AUTOSAR XML (schema 4-2-2)
package /STELLANTIS/EPT/ASWCs
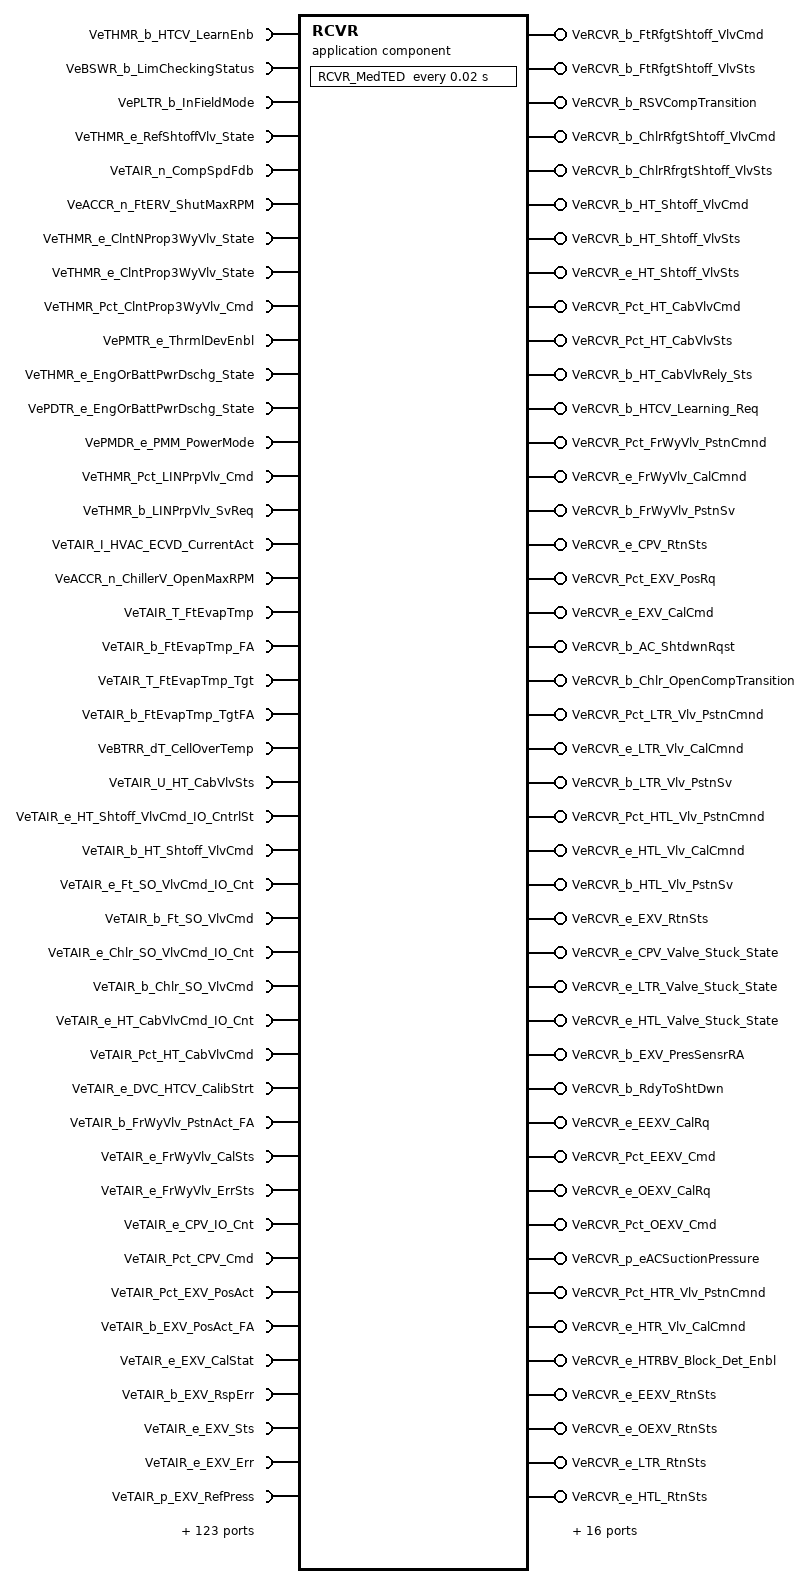
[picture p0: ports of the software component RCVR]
  application sw component type RCVR
    156 x require port:
      VeTHMR_b_HTCV_LearnEnb: variation-point={short-label=vpVeTHMR_b_HTCV_LearnEnb, sw-syscond=1}, nonqueued-receiver-com-spec{data-element=Value, init-value=0}, required-interface=VeTHMR_b_HTCV_LearnEnb
      VeBSWR_b_LimCheckingStatus: variation-point={short-label=vpVeBSWR_b_LimCheckingStatus, sw-syscond=1}, nonqueued-receiver-com-spec{data-element=Value, init-value=0}, required-interface=VeBSWR_b_LimCheckingStatus
      VePLTR_b_InFieldMode: variation-point={short-label=vpVePLTR_b_InFieldMode, sw-syscond=1}, nonqueued-receiver-com-spec{data-element=Value, init-value=0}, required-interface=VePLTR_b_InFieldMode
      VeTHMR_e_RefShtoffVlv_State: variation-point={short-label=vpVeTHMR_e_RefShtoffVlv_State, sw-syscond=1}, nonqueued-receiver-com-spec{data-element=Value, init-value=CeTHMR_e_AllOpen}, required-interface=VeTHMR_e_RefShtoffVlv_State
      VeTAIR_n_CompSpdFdb: variation-point={short-label=vpVeTAIR_n_CompSpdFdb, sw-syscond=1}, nonqueued-receiver-com-spec{data-element=Value, init-value=0}, required-interface=VeTAIR_n_CompSpdFdb
      VeACCR_n_FtERV_ShutMaxRPM: variation-point={short-label=vpVeACCR_n_FtERV_ShutMaxRPM, sw-syscond=1}, nonqueued-receiver-com-spec{data-element=Value, init-value=0}, required-interface=VeACCR_n_FtERV_ShutMaxRPM
      VeTHMR_e_ClntNProp3WyVlv_State: variation-point={short-label=vpVeTHMR_e_ClntNProp3WyVlv_State, sw-syscond=1}, nonqueued-receiver-com-spec{data-element=Value, init-value=CeTHMR_e_NoVlvPwrd}, required-interface=VeTHMR_e_ClntNProp3WyVlv_State
      VeTHMR_e_ClntProp3WyVlv_State: variation-point={short-label=vpVeTHMR_e_ClntProp3WyVlv_State, sw-syscond=1}, nonqueued-receiver-com-spec{data-element=Value, init-value=CeTHMR_e_NoVlvPwrd}, required-interface=VeTHMR_e_ClntProp3WyVlv_State
      VeTHMR_Pct_ClntProp3WyVlv_Cmd: variation-point={short-label=vpVeTHMR_Pct_ClntProp3WyVlv_Cmd, sw-syscond=1}, nonqueued-receiver-com-spec{data-element=Value, init-value=0}, required-interface=VeTHMR_Pct_ClntProp3WyVlv_Cmd
      VePMTR_e_ThrmlDevEnbl: variation-point={short-label=vpVePMTR_e_ThrmlDevEnbl, sw-syscond=1}, nonqueued-receiver-com-spec{data-element=Value, init-value=CePMTR_e_DISBL_All_Thrml}, required-interface=VePMTR_e_ThrmlDevEnbl
      VeTHMR_e_EngOrBattPwrDschg_State: variation-point={short-label=vpVeTHMR_e_EngOrBattPwrDschg_State, sw-syscond=1}, nonqueued-receiver-com-spec{data-element=Value, init-value=CePDTR_e_No_Dischrg}, required-interface=VeTHMR_e_EngOrBattPwrDschg_State
      VePDTR_e_EngOrBattPwrDschg_State: variation-point={short-label=vpVePDTR_e_EngOrBattPwrDschg_State, sw-syscond=1}, nonqueued-receiver-com-spec{data-element=Value, init-value=CePDTR_e_No_Dischrg}, required-interface=VePDTR_e_EngOrBattPwrDschg_State
      VePMDR_e_PMM_PowerMode: variation-point={short-label=vpVePMDR_e_PMM_PowerMode, sw-syscond=1}, nonqueued-receiver-com-spec{data-element=Value, init-value=CePMDR_e_PowerMode_Off}, required-interface=VePMDR_e_PMM_PowerMode
      VeTHMR_Pct_LINPrpVlv_Cmd: variation-point={short-label=vpVeTHMR_Pct_LINPrpVlv_Cmd, sw-syscond=1}, nonqueued-receiver-com-spec{data-element=Value, init-value=0}, required-interface=VeTHMR_Pct_LINPrpVlv_Cmd
      VeTHMR_b_LINPrpVlv_SvReq: variation-point={short-label=vpVeTHMR_b_LINPrpVlv_SvReq, sw-syscond=1}, nonqueued-receiver-com-spec{data-element=Value, init-value=0}, required-interface=VeTHMR_b_LINPrpVlv_SvReq
      VeTAIR_I_HVAC_ECVD_CurrentAct: variation-point={short-label=vpVeTAIR_I_HVAC_ECVD_CurrentAct, sw-syscond=1}, nonqueued-receiver-com-spec{data-element=Value, init-value=0}, required-interface=VeTAIR_I_HVAC_ECVD_CurrentAct
      VeACCR_n_ChillerV_OpenMaxRPM: variation-point={short-label=vpVeACCR_n_ChillerV_OpenMaxRPM, sw-syscond=1}, nonqueued-receiver-com-spec{data-element=Value, init-value=0}, required-interface=VeACCR_n_ChillerV_OpenMaxRPM
      VeTAIR_T_FtEvapTmp: variation-point={short-label=vpVeTAIR_T_FtEvapTmp, sw-syscond=1}, nonqueued-receiver-com-spec{data-element=Value, init-value=0}, required-interface=VeTAIR_T_FtEvapTmp
      VeTAIR_b_FtEvapTmp_FA: variation-point={short-label=vpVeTAIR_b_FtEvapTmp_FA, sw-syscond=1}, nonqueued-receiver-com-spec{data-element=Value, init-value=0}, required-interface=VeTAIR_b_FtEvapTmp_FA
      VeTAIR_T_FtEvapTmp_Tgt: variation-point={short-label=vpVeTAIR_T_FtEvapTmp_Tgt, sw-syscond=1}, nonqueued-receiver-com-spec{data-element=Value, init-value=0}, required-interface=VeTAIR_T_FtEvapTmp_Tgt
      VeTAIR_b_FtEvapTmp_TgtFA: variation-point={short-label=vpVeTAIR_b_FtEvapTmp_TgtFA, sw-syscond=1}, nonqueued-receiver-com-spec{data-element=Value, init-value=0}, required-interface=VeTAIR_b_FtEvapTmp_TgtFA
      VeBTRR_dT_CellOverTemp: variation-point={short-label=vpVeBTRR_dT_CellOverTemp, sw-syscond=1}, nonqueued-receiver-com-spec{data-element=Value, init-value=0}, required-interface=VeBTRR_dT_CellOverTemp
      VeTAIR_U_HT_CabVlvSts: variation-point={short-label=vpVeTAIR_U_HT_CabVlvSts, sw-syscond=1}, nonqueued-receiver-com-spec{data-element=Value, init-value=0}, required-interface=VeTAIR_U_HT_CabVlvSts
      VeTAIR_e_HT_Shtoff_VlvCmd_IO_CntrlSt: variation-point={short-label=vpVeTAIR_e_HT_Shtoff_VlvCmd_IO_CntrlSt, sw-syscond=1}, nonqueued-receiver-com-spec{data-element=Value, init-value=CeTAIR_e_Return_Control_to_ECU}, required-interface=VeTAIR_e_HT_Shtoff_VlvCmd_IO_CntrlSt
      VeTAIR_b_HT_Shtoff_VlvCmd: variation-point={short-label=vpVeTAIR_b_HT_Shtoff_VlvCmd, sw-syscond=1}, nonqueued-receiver-com-spec{data-element=Value, init-value=0}, required-interface=VeTAIR_b_HT_Shtoff_VlvCmd
      VeTAIR_e_Ft_SO_VlvCmd_IO_Cnt: variation-point={short-label=vpVeTAIR_e_Ft_SO_VlvCmd_IO_Cnt, sw-syscond=1}, nonqueued-receiver-com-spec{data-element=Value, init-value=CeTAIR_e_Return_Control_to_ECU}, required-interface=VeTAIR_e_Ft_SO_VlvCmd_IO_Cnt
      VeTAIR_b_Ft_SO_VlvCmd: variation-point={short-label=vpVeTAIR_b_Ft_SO_VlvCmd, sw-syscond=1}, nonqueued-receiver-com-spec{data-element=Value, init-value=0}, required-interface=VeTAIR_b_Ft_SO_VlvCmd
      VeTAIR_e_Chlr_SO_VlvCmd_IO_Cnt: variation-point={short-label=vpVeTAIR_e_Chlr_SO_VlvCmd_IO_Cnt, sw-syscond=1}, nonqueued-receiver-com-spec{data-element=Value, init-value=CeTAIR_e_Return_Control_to_ECU}, required-interface=VeTAIR_e_Chlr_SO_VlvCmd_IO_Cnt
      VeTAIR_b_Chlr_SO_VlvCmd: variation-point={short-label=vpVeTAIR_b_Chlr_SO_VlvCmd, sw-syscond=1}, nonqueued-receiver-com-spec{data-element=Value, init-value=0}, required-interface=VeTAIR_b_Chlr_SO_VlvCmd
      VeTAIR_e_HT_CabVlvCmd_IO_Cnt: variation-point={short-label=vpVeTAIR_e_HT_CabVlvCmd_IO_Cnt, sw-syscond=1}, nonqueued-receiver-com-spec{data-element=Value, init-value=CeTAIR_e_Return_Control_to_ECU}, required-interface=VeTAIR_e_HT_CabVlvCmd_IO_Cnt
      VeTAIR_Pct_HT_CabVlvCmd: variation-point={short-label=vpVeTAIR_Pct_HT_CabVlvCmd, sw-syscond=1}, nonqueued-receiver-com-spec{data-element=Value, init-value=0}, required-interface=VeTAIR_Pct_HT_CabVlvCmd
      VeTAIR_e_DVC_HTCV_CalibStrt: variation-point={short-label=vpVeTAIR_e_DVC_HTCV_CalibStrt, sw-syscond=1}, nonqueued-receiver-com-spec{data-element=Value, init-value=CeTAIR_e_DVC_HTCV_Calibration_Start}, required-interface=VeTAIR_e_DVC_HTCV_CalibStrt
      VeTAIR_b_FrWyVlv_PstnAct_FA: variation-point={short-label=vpVeTAIR_b_FrWyVlv_PstnAct_FA, sw-syscond=1}, nonqueued-receiver-com-spec{data-element=Value, init-value=0}, required-interface=VeTAIR_b_FrWyVlv_PstnAct_FA
      VeTAIR_e_FrWyVlv_CalSts: variation-point={short-label=vpVeTAIR_e_FrWyVlv_CalSts, sw-syscond=1}, nonqueued-receiver-com-spec{data-element=Value, init-value=CeTAIR_e_CPV_Calibration_Complete}, required-interface=VeTAIR_e_FrWyVlv_CalSts
      VeTAIR_e_FrWyVlv_ErrSts: variation-point={short-label=vpVeTAIR_e_FrWyVlv_ErrSts, sw-syscond=1}, nonqueued-receiver-com-spec{data-element=Value, init-value=CeTAIR_e_CPV_Status_OK}, required-interface=VeTAIR_e_FrWyVlv_ErrSts
      VeTAIR_e_CPV_IO_Cnt: variation-point={short-label=vpVeTAIR_e_CPV_IO_Cnt, sw-syscond=1}, nonqueued-receiver-com-spec{data-element=Value, init-value=CeTAIR_e_Return_Control_to_ECU}, required-interface=VeTAIR_e_CPV_IO_Cnt
      VeTAIR_Pct_CPV_Cmd: variation-point={short-label=vpVeTAIR_Pct_CPV_Cmd, sw-syscond=1}, nonqueued-receiver-com-spec{data-element=Value, init-value=0}, required-interface=VeTAIR_Pct_CPV_Cmd
      VeTAIR_Pct_EXV_PosAct: variation-point={short-label=vpVeTAIR_Pct_EXV_PosAct, sw-syscond=1}, nonqueued-receiver-com-spec{data-element=Value, init-value=0}, required-interface=VeTAIR_Pct_EXV_PosAct
      VeTAIR_b_EXV_PosAct_FA: variation-point={short-label=vpVeTAIR_b_EXV_PosAct_FA, sw-syscond=1}, nonqueued-receiver-com-spec{data-element=Value, init-value=0}, required-interface=VeTAIR_b_EXV_PosAct_FA
      VeTAIR_e_EXV_CalStat: variation-point={short-label=vpVeTAIR_e_EXV_CalStat, sw-syscond=1}, nonqueued-receiver-com-spec{data-element=Value, init-value=CeTAIR_e_EXV_Calibration_Complete}, required-interface=VeTAIR_e_EXV_CalStat
      VeTAIR_b_EXV_RspErr: variation-point={short-label=vpVeTAIR_b_EXV_RspErr, sw-syscond=1}, nonqueued-receiver-com-spec{data-element=Value, init-value=0}, required-interface=VeTAIR_b_EXV_RspErr
      VeTAIR_e_EXV_Sts: variation-point={short-label=vpVeTAIR_e_EXV_Sts, sw-syscond=1}, nonqueued-receiver-com-spec{data-element=Value, init-value=CeTAIR_e_EXV_Status_OK}, required-interface=VeTAIR_e_EXV_Sts
      VeTAIR_e_EXV_Err: variation-point={short-label=vpVeTAIR_e_EXV_Err, sw-syscond=1}, nonqueued-receiver-com-spec{data-element=Value, init-value=CeTAIR_e_EXV_ErrorMsg_OK}, required-interface=VeTAIR_e_EXV_Err
      VeTAIR_p_EXV_RefPress: variation-point={short-label=vpVeTAIR_p_EXV_RefPress, sw-syscond=1}, nonqueued-receiver-com-spec{data-element=Value, init-value=0}, required-interface=VeTAIR_p_EXV_RefPress
      VeTAIR_b_EXV_RefPress_FA: variation-point={short-label=vpVeTAIR_b_EXV_RefPress_FA, sw-syscond=1}, nonqueued-receiver-com-spec{data-element=Value, init-value=0}, required-interface=VeTAIR_b_EXV_RefPress_FA
      VeTAIR_T_EXV_RefTemp: variation-point={short-label=vpVeTAIR_T_EXV_RefTemp, sw-syscond=1}, nonqueued-receiver-com-spec{data-element=Value, init-value=0}, required-interface=VeTAIR_T_EXV_RefTemp
      VeTAIR_b_EXV_RefTemp_FA: variation-point={short-label=vpVeTAIR_b_EXV_RefTemp_FA, sw-syscond=1}, nonqueued-receiver-com-spec{data-element=Value, init-value=0}, required-interface=VeTAIR_b_EXV_RefTemp_FA
      VeVLDR_b_HTSoV_StkCls_XYEnbl: variation-point={short-label=vpVeVLDR_b_HTSoV_StkCls_XYEnbl, sw-syscond=1}, nonqueued-receiver-com-spec{data-element=Value, init-value=0}, required-interface=VeVLDR_b_HTSoV_StkCls_XYEnbl
      VeVLDR_b_HTSoV_StkOpn_XYEnbl: variation-point={short-label=vpVeVLDR_b_HTSoV_StkOpn_XYEnbl, sw-syscond=1}, nonqueued-receiver-com-spec{data-element=Value, init-value=0}, required-interface=VeVLDR_b_HTSoV_StkOpn_XYEnbl
      VeVLDR_b_HTSoV_StkCls_FltDtct: variation-point={short-label=vpVeVLDR_b_HTSoV_StkCls_FltDtct, sw-syscond=1}, nonqueued-receiver-com-spec{data-element=Value, init-value=0}, required-interface=VeVLDR_b_HTSoV_StkCls_FltDtct
      VeVLDR_b_HTSoV_StkOpn_FltDtct: variation-point={short-label=vpVeVLDR_b_HTSoV_StkOpn_FltDtct, sw-syscond=1}, nonqueued-receiver-com-spec{data-element=Value, init-value=0}, required-interface=VeVLDR_b_HTSoV_StkOpn_FltDtct
      VeVLDR_b_HTCV_Stck_FltDtct: variation-point={short-label=vpVeVLDR_b_HTCV_Stck_FltDtct, sw-syscond=1}, nonqueued-receiver-com-spec{data-element=Value, init-value=0}, required-interface=VeVLDR_b_HTCV_Stck_FltDtct
      VeVLDR_b_HCTV_Leak_FltDtct: variation-point={short-label=vpVeVLDR_b_HCTV_Leak_FltDtct, sw-syscond=1}, nonqueued-receiver-com-spec{data-element=Value, init-value=0}, required-interface=VeVLDR_b_HCTV_Leak_FltDtct
      VeVLDR_b_EXV_PressElctrFlt_FltDtct: variation-point={short-label=vpVeVLDR_b_EXV_PressElctrFlt_FltDtct, sw-syscond=1}, nonqueued-receiver-com-spec{data-element=Value, init-value=0}, required-interface=VeVLDR_b_EXV_PressElctrFlt_FltDtct
      VeVLDR_b_EXV_TempElctrFlt_FltDtct: variation-point={short-label=vpVeVLDR_b_EXV_TempElctrFlt_FltDtct, sw-syscond=1}, nonqueued-receiver-com-spec{data-element=Value, init-value=0}, required-interface=VeVLDR_b_EXV_TempElctrFlt_FltDtct
      VeTAIR_b_LTR_BypsVlv_ActlPstn_FA: variation-point={short-label=vpVeTAIR_b_LTR_BypsVlv_ActlPstn_FA, sw-syscond=1}, nonqueued-receiver-com-spec{data-element=Value, init-value=0}, required-interface=VeTAIR_b_LTR_BypsVlv_ActlPstn_FA
      VeTAIR_e_LTR_BypsVlv_ErrSts: variation-point={short-label=vpVeTAIR_e_LTR_BypsVlv_ErrSts, sw-syscond=1}, nonqueued-receiver-com-spec{data-element=Value, init-value=CeTAIR_e_CPV_Status_OK}, required-interface=VeTAIR_e_LTR_BypsVlv_ErrSts
      VeTAIR_e_LTR_BypsVlv_CalSts: variation-point={short-label=vpVeTAIR_e_LTR_BypsVlv_CalSts, sw-syscond=1}, nonqueued-receiver-com-spec{data-element=Value, init-value=CeTAIR_e_CPV_Calibration_Complete}, required-interface=VeTAIR_e_LTR_BypsVlv_CalSts
      VeTAIR_b_HTL_BypsVlv_ActlPstn_FA: variation-point={short-label=vpVeTAIR_b_HTL_BypsVlv_ActlPstn_FA, sw-syscond=1}, nonqueued-receiver-com-spec{data-element=Value, init-value=0}, required-interface=VeTAIR_b_HTL_BypsVlv_ActlPstn_FA
      VeTAIR_e_HTL_BypsVlv_ErrSts: variation-point={short-label=vpVeTAIR_e_HTL_BypsVlv_ErrSts, sw-syscond=1}, nonqueued-receiver-com-spec{data-element=Value, init-value=CeTAIR_e_CPV_Status_OK}, required-interface=VeTAIR_e_HTL_BypsVlv_ErrSts
      VeTAIR_e_HTL_BypsVlv_CalSts: variation-point={short-label=vpVeTAIR_e_HTL_BypsVlv_CalSts, sw-syscond=1}, nonqueued-receiver-com-spec{data-element=Value, init-value=CeTAIR_e_CPV_Calibration_Complete}, required-interface=VeTAIR_e_HTL_BypsVlv_CalSts
      VeTAIR_e_EXV_IO_CntrlSt: variation-point={short-label=vpVeTAIR_e_EXV_IO_CntrlSt, sw-syscond=1}, nonqueued-receiver-com-spec{data-element=Value, init-value=CeTAIR_e_Return_Control_to_ECU}, required-interface=VeTAIR_e_EXV_IO_CntrlSt
      VeTAIR_Pct_EXV_Cmd: variation-point={short-label=vpVeTAIR_Pct_EXV_Cmd, sw-syscond=1}, nonqueued-receiver-com-spec{data-element=Value, init-value=0}, required-interface=VeTAIR_Pct_EXV_Cmd
      VeTAIR_b_DVC_EXV_Calibration_Start: variation-point={short-label=vpVeTAIR_b_DVC_EXV_Calibration_Start, sw-syscond=1}, nonqueued-receiver-com-spec{data-element=Value, init-value=0}, required-interface=VeTAIR_b_DVC_EXV_Calibration_Start
      VeTAIR_e_LT_Shtoff_VlvCmd_IO_CntrlSt: variation-point={short-label=vpVeTAIR_e_LT_Shtoff_VlvCmd_IO_CntrlSt, sw-syscond=1}, nonqueued-receiver-com-spec{data-element=Value, init-value=CeTAIR_e_Return_Control_to_ECU}, required-interface=VeTAIR_e_LT_Shtoff_VlvCmd_IO_CntrlSt
      VeTAIR_b_LT_Shtoff_VlvCmd: variation-point={short-label=vpVeTAIR_b_LT_Shtoff_VlvCmd, sw-syscond=1}, nonqueued-receiver-com-spec{data-element=Value, init-value=0}, required-interface=VeTAIR_b_LT_Shtoff_VlvCmd
      VeVLDR_b_EXV_PressSens_FltDtct: variation-point={short-label=vpVeVLDR_b_EXV_PressSens_FltDtct, sw-syscond=1}, nonqueued-receiver-com-spec{data-element=Value, init-value=0}, required-interface=VeVLDR_b_EXV_PressSens_FltDtct
      VeVLDR_b_EXV_TempSens_FltDtct: variation-point={short-label=vpVeVLDR_b_EXV_TempSens_FltDtct, sw-syscond=1}, nonqueued-receiver-com-spec{data-element=Value, init-value=0}, required-interface=VeVLDR_b_EXV_TempSens_FltDtct
      VeTHMR_Pct_HTL_BypsVlv_Cmd: variation-point={short-label=vpVeTHMR_Pct_HTL_BypsVlv_Cmd, sw-syscond=1}, nonqueued-receiver-com-spec{data-element=Value, init-value=0}, required-interface=VeTHMR_Pct_HTL_BypsVlv_Cmd
      VeTHMR_Pct_LTL_Vlv_Cmd: variation-point={short-label=vpVeTHMR_Pct_LTL_Vlv_Cmd, sw-syscond=1}, nonqueued-receiver-com-spec{data-element=Value, init-value=0}, required-interface=VeTHMR_Pct_LTL_Vlv_Cmd
      VeTAIR_Pct_FrWyVlv_PstnAct: variation-point={short-label=vpVeTAIR_Pct_FrWyVlv_PstnAct, sw-syscond=1}, nonqueued-receiver-com-spec{data-element=Value, init-value=0}, required-interface=VeTAIR_Pct_FrWyVlv_PstnAct
      VeTAIR_Pct_LTR_BypsVlv_ActlPstn: variation-point={short-label=vpVeTAIR_Pct_LTR_BypsVlv_ActlPstn, sw-syscond=1}, nonqueued-receiver-com-spec{data-element=Value, init-value=0}, required-interface=VeTAIR_Pct_LTR_BypsVlv_ActlPstn
      VeTAIR_Pct_HTL_BypsVlv_ActlPstn: variation-point={short-label=vpVeTAIR_Pct_HTL_BypsVlv_ActlPstn, sw-syscond=1}, nonqueued-receiver-com-spec{data-element=Value, init-value=0}, required-interface=VeTAIR_Pct_HTL_BypsVlv_ActlPstn
      VeTAIR_e_LTR_BypsVlv_IO_CntrlSt: variation-point={short-label=vpVeTAIR_e_LTR_BypsVlv_IO_CntrlSt, sw-syscond=1}, nonqueued-receiver-com-spec{data-element=Value, init-value=CeTAIR_e_Return_Control_to_ECU}, required-interface=VeTAIR_e_LTR_BypsVlv_IO_CntrlSt
      VeTAIR_Pct_LTR_BypsVlv_Cmd: variation-point={short-label=vpVeTAIR_Pct_LTR_BypsVlv_Cmd, sw-syscond=1}, nonqueued-receiver-com-spec{data-element=Value, init-value=0}, required-interface=VeTAIR_Pct_LTR_BypsVlv_Cmd
      VeTAIR_e_HTL_BypsVlv_IO_CntrlSt: variation-point={short-label=vpVeTAIR_e_HTL_BypsVlv_IO_CntrlSt, sw-syscond=1}, nonqueued-receiver-com-spec{data-element=Value, init-value=CeTAIR_e_Return_Control_to_ECU}, required-interface=VeTAIR_e_HTL_BypsVlv_IO_CntrlSt
      VeTAIR_Pct_HTL_BypsVlv_Cmd: variation-point={short-label=vpVeTAIR_Pct_HTL_BypsVlv_Cmd, sw-syscond=1}, nonqueued-receiver-com-spec{data-element=Value, init-value=0}, required-interface=VeTAIR_Pct_HTL_BypsVlv_Cmd
      VeVLDR_b_EXV_PressShrtHigh: variation-point={short-label=vpVeVLDR_b_EXV_PressShrtHigh, sw-syscond=1}, nonqueued-receiver-com-spec{data-element=Value, init-value=0}, required-interface=VeVLDR_b_EXV_PressShrtHigh
      VeCITR_e_FOTA_Install_Type: variation-point={short-label=vpVeCITR_e_FOTA_Install_Type, sw-syscond=1}, nonqueued-receiver-com-spec{data-element=Value, init-value=CeCITR_e_NoFOTA}, required-interface=VeCITR_e_FOTA_Install_Type
      VeTAIR_T_EEXV_RefTemp: variation-point={short-label=vpVeTAIR_T_EEXV_RefTemp, sw-syscond=1}, nonqueued-receiver-com-spec{data-element=Value, init-value=0}, required-interface=VeTAIR_T_EEXV_RefTemp
      VeTAIR_p_EEXV_RefPress: variation-point={short-label=vpVeTAIR_p_EEXV_RefPress, sw-syscond=1}, nonqueued-receiver-com-spec{data-element=Value, init-value=0}, required-interface=VeTAIR_p_EEXV_RefPress
      VeTHMR_e_CabHeatThermalMode: variation-point={short-label=vpVeTHMR_e_CabHeatThermalMode, sw-syscond=1}, nonqueued-receiver-com-spec{data-element=Value, init-value=CeTHMR_e_NoActvHeat}, required-interface=VeTHMR_e_CabHeatThermalMode
      VeTHMR_e_CabThermalMode: variation-point={short-label=vpVeTHMR_e_CabThermalMode, sw-syscond=1}, nonqueued-receiver-com-spec{data-element=Value, init-value=CeTHMR_e_Cab_NoConditioning}, required-interface=VeTHMR_e_CabThermalMode
      VeTHMR_e_BatThrmlSt: variation-point={short-label=vpVeTHMR_e_BatThrmlSt, sw-syscond=1}, nonqueued-receiver-com-spec{data-element=Value, init-value=CeTHMR_e_NoConditioning}, required-interface=VeTHMR_e_BatThrmlSt
      VeTHMR_e_LTCLThrmlMode: variation-point={short-label=vpVeTHMR_e_LTCLThrmlMode, sw-syscond=1}, nonqueued-receiver-com-spec{data-element=Value, init-value=CeTHMR_e_LTCLBalancing}, required-interface=VeTHMR_e_LTCLThrmlMode
      VeTHMR_b_DeiceActv: variation-point={short-label=vpVeTHMR_b_DeiceActv, sw-syscond=1}, nonqueued-receiver-com-spec{data-element=Value, init-value=0}, required-interface=VeTHMR_b_DeiceActv
      VeTAIR_T_OEXV_OutTempSens: variation-point={short-label=vpVeTAIR_T_OEXV_OutTempSens, sw-syscond=1}, nonqueued-receiver-com-spec{data-element=Value, init-value=0}, required-interface=VeTAIR_T_OEXV_OutTempSens
      VeTAIR_p_OEXV_OutPressSens: variation-point={short-label=vpVeTAIR_p_OEXV_OutPressSens, sw-syscond=1}, nonqueued-receiver-com-spec{data-element=Value, init-value=0}, required-interface=VeTAIR_p_OEXV_OutPressSens
      VeTAIR_T_OEXV_InTempSens: variation-point={short-label=vpVeTAIR_T_OEXV_InTempSens, sw-syscond=1}, nonqueued-receiver-com-spec{data-element=Value, init-value=0}, required-interface=VeTAIR_T_OEXV_InTempSens
      VeTAIR_p_HghRfrgtPres: variation-point={short-label=vpVeTAIR_p_HghRfrgtPres, sw-syscond=1}, nonqueued-receiver-com-spec{data-element=Value, init-value=0}, required-interface=VeTAIR_p_HghRfrgtPres
      VeAATR_T_EstAmbAirTemp: variation-point={short-label=vpVeAATR_T_EstAmbAirTemp, sw-syscond=1}, nonqueued-receiver-com-spec{data-element=Value, init-value=0}, required-interface=VeAATR_T_EstAmbAirTemp
      VeAATR_b_EstAmbAirTempFA: variation-point={short-label=vpVeAATR_b_EstAmbAirTempFA, sw-syscond=1}, nonqueued-receiver-com-spec{data-element=Value, init-value=0}, required-interface=VeAATR_b_EstAmbAirTempFA
      VeTRIR_T_HtrCorClnt_TmpIn: variation-point={short-label=vpVeTRIR_T_HtrCorClnt_TmpIn, sw-syscond=1}, nonqueued-receiver-com-spec{data-element=Value, init-value=0}, required-interface=VeTRIR_T_HtrCorClnt_TmpIn
      VeTRIR_b_HtrCorClnt_TmpIn_FA: variation-point={short-label=vpVeTRIR_b_HtrCorClnt_TmpIn_FA, sw-syscond=1}, nonqueued-receiver-com-spec{data-element=Value, init-value=0}, required-interface=VeTRIR_b_HtrCorClnt_TmpIn_FA
      VeTAIR_T_HtrCoreTmp_Tgt: variation-point={short-label=vpVeTAIR_T_HtrCoreTmp_Tgt, sw-syscond=1}, nonqueued-receiver-com-spec{data-element=Value, init-value=0}, required-interface=VeTAIR_T_HtrCoreTmp_Tgt
      VeTHMR_e_CabCoolThermalState: variation-point={short-label=vpVeTHMR_e_CabCoolThermalState, sw-syscond=1}, nonqueued-receiver-com-spec{data-element=Value, init-value=CeTHMR_e_NoCabinCooling}, required-interface=VeTHMR_e_CabCoolThermalState
      VeTAIR_Pct_EEXV_PosAct: variation-point={short-label=vpVeTAIR_Pct_EEXV_PosAct, sw-syscond=1}, nonqueued-receiver-com-spec{data-element=Value, init-value=0}, required-interface=VeTAIR_Pct_EEXV_PosAct
      VeTAIR_e_EEXV_Sts: variation-point={short-label=vpVeTAIR_e_EEXV_Sts, sw-syscond=1}, nonqueued-receiver-com-spec{data-element=Value, init-value=CeTAIR_e_EXV_Status_OK}, required-interface=VeTAIR_e_EEXV_Sts
      VeTAIR_e_EEXV_CalStat: variation-point={short-label=vpVeTAIR_e_EEXV_CalStat, sw-syscond=1}, nonqueued-receiver-com-spec{data-element=Value, init-value=CeTAIR_e_EXV_Calibration_Complete}, required-interface=VeTAIR_e_EEXV_CalStat
      VeTAIR_e_OEXV_Sts: variation-point={short-label=vpVeTAIR_e_OEXV_Sts, sw-syscond=1}, nonqueued-receiver-com-spec{data-element=Value, init-value=CeTAIR_e_EXV_Status_OK}, required-interface=VeTAIR_e_OEXV_Sts
      VeTAIR_e_OEXV_CalStat: variation-point={short-label=vpVeTAIR_e_OEXV_CalStat, sw-syscond=1}, nonqueued-receiver-com-spec{data-element=Value, init-value=CeTAIR_e_EXV_Calibration_Complete}, required-interface=VeTAIR_e_OEXV_CalStat
      VeDMAB_y_StatusByte_CoolantVlvB_CktHi: variation-point={short-label=vpVeDMAB_y_StatusByte_CoolantVlvB_CktHi, sw-syscond=1}, nonqueued-receiver-com-spec{data-element=Value, init-value=0}, required-interface=VeDMAB_y_StatusByte_CoolantVlvB_CktHi
      VeDMAB_y_StatusByte_CoolantVlvB_Ckt: variation-point={short-label=vpVeDMAB_y_StatusByte_CoolantVlvB_Ckt, sw-syscond=1}, nonqueued-receiver-com-spec{data-element=Value, init-value=0}, required-interface=VeDMAB_y_StatusByte_CoolantVlvB_Ckt
      VeDMAB_y_StatusByte_LostCommACRefrigExpVlvActA: variation-point={short-label=vpVeDMAB_y_StatusByte_LostCommACRefrigExpVlvActA, sw-syscond=1}, nonqueued-receiver-com-spec{data-element=Value, init-value=0}, required-interface=VeDMAB_y_StatusByte_LostCommACRefrigExpVlvActA
      VeDMAB_y_StatusByte_HB_PSC_CtrlValCCktPerf: variation-point={short-label=vpVeDMAB_y_StatusByte_HB_PSC_CtrlValCCktPerf, sw-syscond=1}, nonqueued-receiver-com-spec{data-element=Value, init-value=0}, required-interface=VeDMAB_y_StatusByte_HB_PSC_CtrlValCCktPerf
      VeDMAB_y_StatusByte_LostCommHB_PSCCooCtrlVlvC: variation-point={short-label=vpVeDMAB_y_StatusByte_LostCommHB_PSCCooCtrlVlvC, sw-syscond=1}, nonqueued-receiver-com-spec{data-element=Value, init-value=0}, required-interface=VeDMAB_y_StatusByte_LostCommHB_PSCCooCtrlVlvC
      VeDMAB_y_StatusByte_HB_PSC_CtrlValACktPerf: variation-point={short-label=vpVeDMAB_y_StatusByte_HB_PSC_CtrlValACktPerf, sw-syscond=1}, nonqueued-receiver-com-spec{data-element=Value, init-value=0}, required-interface=VeDMAB_y_StatusByte_HB_PSC_CtrlValACktPerf
      VeDMAB_y_StatusByte_LosCommHybPSCCtrlValA: variation-point={short-label=vpVeDMAB_y_StatusByte_LosCommHybPSCCtrlValA, sw-syscond=1}, nonqueued-receiver-com-spec{data-element=Value, init-value=0}, required-interface=VeDMAB_y_StatusByte_LosCommHybPSCCtrlValA
      VeDMAB_y_StatusByte_LIN1_BusOff: variation-point={short-label=vpVeDMAB_y_StatusByte_LIN1_BusOff, sw-syscond=1}, nonqueued-receiver-com-spec{data-element=Value, init-value=0}, required-interface=VeDMAB_y_StatusByte_LIN1_BusOff
      VeDMAB_y_StatusByte_HB_PSC_CtrlValBCktPerf: variation-point={short-label=vpVeDMAB_y_StatusByte_HB_PSC_CtrlValBCktPerf, sw-syscond=1}, nonqueued-receiver-com-spec{data-element=Value, init-value=0}, required-interface=VeDMAB_y_StatusByte_HB_PSC_CtrlValBCktPerf
      VeDMAB_y_StatusByte_LostCommHB_PSCCooCtrlVlvB: variation-point={short-label=vpVeDMAB_y_StatusByte_LostCommHB_PSCCooCtrlVlvB, sw-syscond=1}, nonqueued-receiver-com-spec{data-element=Value, init-value=0}, required-interface=VeDMAB_y_StatusByte_LostCommHB_PSCCooCtrlVlvB
      VeDMAB_y_StatusByte_CoolCtrlVlv1CktHi: variation-point={short-label=vpVeDMAB_y_StatusByte_CoolCtrlVlv1CktHi, sw-syscond=1}, nonqueued-receiver-com-spec{data-element=Value, init-value=0}, required-interface=VeDMAB_y_StatusByte_CoolCtrlVlv1CktHi
      VeDMAB_y_StatusByte_CoolCtrlVlv1CktLo: variation-point={short-label=vpVeDMAB_y_StatusByte_CoolCtrlVlv1CktLo, sw-syscond=1}, nonqueued-receiver-com-spec{data-element=Value, init-value=0}, required-interface=VeDMAB_y_StatusByte_CoolCtrlVlv1CktLo
      VeDMAB_y_StatusByte_CoolCtrlVlv1Ckt: variation-point={short-label=vpVeDMAB_y_StatusByte_CoolCtrlVlv1Ckt, sw-syscond=1}, nonqueued-receiver-com-spec{data-element=Value, init-value=0}, required-interface=VeDMAB_y_StatusByte_CoolCtrlVlv1Ckt
      VeDMAB_y_StatusByte_EvapRefriShutoffCtrlCktFlt: variation-point={short-label=vpVeDMAB_y_StatusByte_EvapRefriShutoffCtrlCktFlt, sw-syscond=1}, nonqueued-receiver-com-spec{data-element=Value, init-value=0}, required-interface=VeDMAB_y_StatusByte_EvapRefriShutoffCtrlCktFlt
      VeDMAB_y_StatusByte_EvapRefriShutoffCtrlshrtBattFlt: variation-point={short-label=vpVeDMAB_y_StatusByte_EvapRefriShutoffCtrlshrtBattFlt, sw-syscond=1}, nonqueued-receiver-com-spec{data-element=Value, init-value=0}, required-interface=VeDMAB_y_StatusByte_EvapRefriShutoffCtrlshrtBattFlt
      VeDMAB_y_StatusByte_EvapRefrishutoffCtrlShrtGndFlt: variation-point={short-label=vpVeDMAB_y_StatusByte_EvapRefrishutoffCtrlShrtGndFlt, sw-syscond=1}, nonqueued-receiver-com-spec{data-element=Value, init-value=0}, required-interface=VeDMAB_y_StatusByte_EvapRefrishutoffCtrlShrtGndFlt
      VeDMAB_y_StatusByte_CoolantVlvA_CktHi: variation-point={short-label=vpVeDMAB_y_StatusByte_CoolantVlvA_CktHi, sw-syscond=1}, nonqueued-receiver-com-spec{data-element=Value, init-value=0}, required-interface=VeDMAB_y_StatusByte_CoolantVlvA_CktHi
      VeDMAB_y_StatusByte_CoolantVlvA_CktLo: variation-point={short-label=vpVeDMAB_y_StatusByte_CoolantVlvA_CktLo, sw-syscond=1}, nonqueued-receiver-com-spec{data-element=Value, init-value=0}, required-interface=VeDMAB_y_StatusByte_CoolantVlvA_CktLo
      VeDMAB_y_StatusByte_CoolantVlvA_Ckt: variation-point={short-label=vpVeDMAB_y_StatusByte_CoolantVlvA_Ckt, sw-syscond=1}, nonqueued-receiver-com-spec{data-element=Value, init-value=0}, required-interface=VeDMAB_y_StatusByte_CoolantVlvA_Ckt
      VeDMAB_y_StatusByte_LIN2_BusOff: variation-point={short-label=vpVeDMAB_y_StatusByte_LIN2_BusOff, sw-syscond=1}, nonqueued-receiver-com-spec{data-element=Value, init-value=0}, required-interface=VeDMAB_y_StatusByte_LIN2_BusOff
      VeTAIR_e_EEXV_IO_CntrlSt: variation-point={short-label=vpVeTAIR_e_EEXV_IO_CntrlSt, sw-syscond=1}, nonqueued-receiver-com-spec{data-element=Value, init-value=CeTAIR_e_Return_Control_to_ECU}, required-interface=VeTAIR_e_EEXV_IO_CntrlSt
      VeTAIR_b_DVC_EEXV_Calibration_Start: variation-point={short-label=vpVeTAIR_b_DVC_EEXV_Calibration_Start, sw-syscond=1}, nonqueued-receiver-com-spec{data-element=Value, init-value=0}, required-interface=VeTAIR_b_DVC_EEXV_Calibration_Start
      VeTAIR_Pct_EEXV_Cmd: variation-point={short-label=vpVeTAIR_Pct_EEXV_Cmd, sw-syscond=1}, nonqueued-receiver-com-spec{data-element=Value, init-value=0}, required-interface=VeTAIR_Pct_EEXV_Cmd
      VeTAIR_e_OEXV_IO_CntrlSt: variation-point={short-label=vpVeTAIR_e_OEXV_IO_CntrlSt, sw-syscond=1}, nonqueued-receiver-com-spec{data-element=Value, init-value=CeTAIR_e_Return_Control_to_ECU}, required-interface=VeTAIR_e_OEXV_IO_CntrlSt
      VeTAIR_b_DVC_OEXV_Calibration_Start: variation-point={short-label=vpVeTAIR_b_DVC_OEXV_Calibration_Start, sw-syscond=1}, nonqueued-receiver-com-spec{data-element=Value, init-value=0}, required-interface=VeTAIR_b_DVC_OEXV_Calibration_Start
      VeTAIR_Pct_OEXV_Cmd: variation-point={short-label=vpVeTAIR_Pct_OEXV_Cmd, sw-syscond=1}, nonqueued-receiver-com-spec{data-element=Value, init-value=0}, required-interface=VeTAIR_Pct_OEXV_Cmd
      VeTAIR_T_CEXV_OutTempSens: variation-point={short-label=vpVeTAIR_T_CEXV_OutTempSens, sw-syscond=1}, nonqueued-receiver-com-spec{data-element=Value, init-value=0}, required-interface=VeTAIR_T_CEXV_OutTempSens
      VeTAIR_p_CEXV_OutPressSens: variation-point={short-label=vpVeTAIR_p_CEXV_OutPressSens, sw-syscond=1}, nonqueued-receiver-com-spec{data-element=Value, init-value=0}, required-interface=VeTAIR_p_CEXV_OutPressSens
      VeSSDR_b_PrepareToShtdwn: variation-point={short-label=vpVeSSDR_b_PrepareToShtdwn, sw-syscond=1}, nonqueued-receiver-com-spec{data-element=Value, init-value=0}, required-interface=VeSSDR_b_PrepareToShtdwn
      VeDCAB_e_Routine_RC1309_CPV_ClbrtnRtn_Op: nonqueued-receiver-com-spec{data-element=Value, init-value=CeDCAB_e_Routine_NOP}, required-interface=VeDCAB_e_Routine_RC1309_CPV_ClbrtnRtn_Op
      VeDCAB_e_Routine_RC130E_LTR_ClbrtnRtn_Op: nonqueued-receiver-com-spec{data-element=Value, init-value=CeDCAB_e_Routine_NOP}, required-interface=VeDCAB_e_Routine_RC130E_LTR_ClbrtnRtn_Op
      VeDCAB_e_Routine_RC130F_HTL_ClbrtnRtn_Op: nonqueued-receiver-com-spec{data-element=Value, init-value=CeDCAB_e_Routine_NOP}, required-interface=VeDCAB_e_Routine_RC130F_HTL_ClbrtnRtn_Op
      VeACCR_b_OilMigOpnVlv: variation-point={short-label=vpVeACCR_b_OilMigOpnVlv, sw-syscond=1}, nonqueued-receiver-com-spec{data-element=Value, init-value=0}, required-interface=VeACCR_b_OilMigOpnVlv
      VeDMAB_y_StatusByte_AC_RefrigTempSnsrCPerf: variation-point={short-label=vpVeDMAB_y_StatusByte_AC_RefrigTempSnsrCPerf, sw-syscond=1}, nonqueued-receiver-com-spec{data-element=Value, init-value=0}, required-interface=VeDMAB_y_StatusByte_AC_RefrigTempSnsrCPerf
      VeDMAB_y_StatusByte_AC_RefrigPresSnsrCCktPerf: variation-point={short-label=vpVeDMAB_y_StatusByte_AC_RefrigPresSnsrCCktPerf, sw-syscond=1}, nonqueued-receiver-com-spec{data-element=Value, init-value=0}, required-interface=VeDMAB_y_StatusByte_AC_RefrigPresSnsrCCktPerf
      VeDMAB_y_StatusByte_AC_RefrigExpVlvAct_C_CntrlCktPerf: variation-point={short-label=vpVeDMAB_y_StatusByte_AC_RefrigExpVlvAct_C_CntrlCktPerf, sw-syscond=1}, nonqueued-receiver-com-spec{data-element=Value, init-value=0}, required-interface=VeDMAB_y_StatusByte_AC_RefrigExpVlvAct_C_CntrlCktPerf
      VeDMAB_y_StatusByte_AC_RefrigPresSnsrCCkt: variation-point={short-label=vpVeDMAB_y_StatusByte_AC_RefrigPresSnsrCCkt, sw-syscond=1}, nonqueued-receiver-com-spec{data-element=Value, init-value=0}, required-interface=VeDMAB_y_StatusByte_AC_RefrigPresSnsrCCkt
      VeDMAB_y_StatusByte_AC_RefrigTempSnsrCCkt: variation-point={short-label=vpVeDMAB_y_StatusByte_AC_RefrigTempSnsrCCkt, sw-syscond=1}, nonqueued-receiver-com-spec{data-element=Value, init-value=0}, required-interface=VeDMAB_y_StatusByte_AC_RefrigTempSnsrCCkt
      VeDMAB_y_StatusByte_LostCommACRefrigExpVlvActC: variation-point={short-label=vpVeDMAB_y_StatusByte_LostCommACRefrigExpVlvActC, sw-syscond=1}, nonqueued-receiver-com-spec{data-element=Value, init-value=0}, required-interface=VeDMAB_y_StatusByte_LostCommACRefrigExpVlvActC
      VeDMAB_y_StatusByte_AC_RefrigTempSnsrAPerf: variation-point={short-label=vpVeDMAB_y_StatusByte_AC_RefrigTempSnsrAPerf, sw-syscond=1}, nonqueued-receiver-com-spec{data-element=Value, init-value=0}, required-interface=VeDMAB_y_StatusByte_AC_RefrigTempSnsrAPerf
      VeDMAB_y_StatusByte_AC_RefrigTempSnsrBCkt: variation-point={short-label=vpVeDMAB_y_StatusByte_AC_RefrigTempSnsrBCkt, sw-syscond=1}, nonqueued-receiver-com-spec{data-element=Value, init-value=0}, required-interface=VeDMAB_y_StatusByte_AC_RefrigTempSnsrBCkt
      VeDMAB_y_StatusByte_AC_RefrigTempSnsrACkt: variation-point={short-label=vpVeDMAB_y_StatusByte_AC_RefrigTempSnsrACkt, sw-syscond=1}, nonqueued-receiver-com-spec{data-element=Value, init-value=0}, required-interface=VeDMAB_y_StatusByte_AC_RefrigTempSnsrACkt
      VeDMAB_y_StatusByte_LIN3_BusOff: variation-point={short-label=vpVeDMAB_y_StatusByte_LIN3_BusOff, sw-syscond=1}, nonqueued-receiver-com-spec{data-element=Value, init-value=0}, required-interface=VeDMAB_y_StatusByte_LIN3_BusOff
      VeDMAB_y_StatusByte_AC_RefrigExpVlvActD_CntrlCktPerf: variation-point={short-label=vpVeDMAB_y_StatusByte_AC_RefrigExpVlvActD_CntrlCktPerf, sw-syscond=1}, nonqueued-receiver-com-spec{data-element=Value, init-value=0}, required-interface=VeDMAB_y_StatusByte_AC_RefrigExpVlvActD_CntrlCktPerf
      VeDMAB_y_StatusByte_AC_RefrigTempSnsrBPerf: variation-point={short-label=vpVeDMAB_y_StatusByte_AC_RefrigTempSnsrBPerf, sw-syscond=1}, nonqueued-receiver-com-spec{data-element=Value, init-value=0}, required-interface=VeDMAB_y_StatusByte_AC_RefrigTempSnsrBPerf
      VeDMAB_y_StatusByte_AC_RefrigTempSnsr5CktPerf: variation-point={short-label=vpVeDMAB_y_StatusByte_AC_RefrigTempSnsr5CktPerf, sw-syscond=1}, nonqueued-receiver-com-spec{data-element=Value, init-value=0}, required-interface=VeDMAB_y_StatusByte_AC_RefrigTempSnsr5CktPerf
      VeDMAB_y_StatusByte_AC_RefrigPresSnsrDCktPerf: variation-point={short-label=vpVeDMAB_y_StatusByte_AC_RefrigPresSnsrDCktPerf, sw-syscond=1}, nonqueued-receiver-com-spec{data-element=Value, init-value=0}, required-interface=VeDMAB_y_StatusByte_AC_RefrigPresSnsrDCktPerf
      VeDMAB_y_StatusByte_AC_RefrigTempSnsr4CktPerf: variation-point={short-label=vpVeDMAB_y_StatusByte_AC_RefrigTempSnsr4CktPerf, sw-syscond=1}, nonqueued-receiver-com-spec{data-element=Value, init-value=0}, required-interface=VeDMAB_y_StatusByte_AC_RefrigTempSnsr4CktPerf
      VeDMAB_y_StatusByte_AC_RefrigTempSnsr5CktShotoGro: variation-point={short-label=vpVeDMAB_y_StatusByte_AC_RefrigTempSnsr5CktShotoGro, sw-syscond=1}, nonqueued-receiver-com-spec{data-element=Value, init-value=0}, required-interface=VeDMAB_y_StatusByte_AC_RefrigTempSnsr5CktShotoGro
      VeDMAB_y_StatusByte_AC_RefrigTempSnsr5CktShotoBat: variation-point={short-label=vpVeDMAB_y_StatusByte_AC_RefrigTempSnsr5CktShotoBat, sw-syscond=1}, nonqueued-receiver-com-spec{data-element=Value, init-value=0}, required-interface=VeDMAB_y_StatusByte_AC_RefrigTempSnsr5CktShotoBat
      VeDMAB_y_StatusByte_AC_RefrigTempSnsrDCkt: variation-point={short-label=vpVeDMAB_y_StatusByte_AC_RefrigTempSnsrDCkt, sw-syscond=1}, nonqueued-receiver-com-spec{data-element=Value, init-value=0}, required-interface=VeDMAB_y_StatusByte_AC_RefrigTempSnsrDCkt
      VeDMAB_y_StatusByte_AC_RefrigPresSnsrDCkt: variation-point={short-label=vpVeDMAB_y_StatusByte_AC_RefrigPresSnsrDCkt, sw-syscond=1}, nonqueued-receiver-com-spec{data-element=Value, init-value=0}, required-interface=VeDMAB_y_StatusByte_AC_RefrigPresSnsrDCkt
      VeDMAB_y_StatusByte_AC_RefrigPresSnsrALo: variation-point={short-label=vpVeDMAB_y_StatusByte_AC_RefrigPresSnsrALo, sw-syscond=1}, nonqueued-receiver-com-spec{data-element=Value, init-value=0}, required-interface=VeDMAB_y_StatusByte_AC_RefrigPresSnsrALo
      VeDMAB_y_StatusByte_AC_RefrigPresSnsrAHi: variation-point={short-label=vpVeDMAB_y_StatusByte_AC_RefrigPresSnsrAHi, sw-syscond=1}, nonqueued-receiver-com-spec{data-element=Value, init-value=0}, required-interface=VeDMAB_y_StatusByte_AC_RefrigPresSnsrAHi
      VeDMAB_y_StatusByte_AC_RefrigPresSnsrAPerf: variation-point={short-label=vpVeDMAB_y_StatusByte_AC_RefrigPresSnsrAPerf, sw-syscond=1}, nonqueued-receiver-com-spec{data-element=Value, init-value=0}, required-interface=VeDMAB_y_StatusByte_AC_RefrigPresSnsrAPerf
    49 x provide port:
      VeRCVR_b_FtRfgtShtoff_VlvCmd: nonqueued-sender-com-spec{data-element=Value, init-value=0}, provided-interface=VeRCVR_b_FtRfgtShtoff_VlvCmd
      VeRCVR_b_FtRfgtShtoff_VlvSts: nonqueued-sender-com-spec{data-element=Value, init-value=0}, provided-interface=VeRCVR_b_FtRfgtShtoff_VlvSts
      VeRCVR_b_RSVCompTransition: nonqueued-sender-com-spec{data-element=Value, init-value=0}, provided-interface=VeRCVR_b_RSVCompTransition
      VeRCVR_b_ChlrRfgtShtoff_VlvCmd: nonqueued-sender-com-spec{data-element=Value, init-value=0}, provided-interface=VeRCVR_b_ChlrRfgtShtoff_VlvCmd
      VeRCVR_b_ChlrRfrgtShtoff_VlvSts: nonqueued-sender-com-spec{data-element=Value, init-value=0}, provided-interface=VeRCVR_b_ChlrRfrgtShtoff_VlvSts
      VeRCVR_b_HT_Shtoff_VlvCmd: nonqueued-sender-com-spec{data-element=Value, init-value=0}, provided-interface=VeRCVR_b_HT_Shtoff_VlvCmd
      VeRCVR_b_HT_Shtoff_VlvSts: nonqueued-sender-com-spec{data-element=Value, init-value=0}, provided-interface=VeRCVR_b_HT_Shtoff_VlvSts
      VeRCVR_e_HT_Shtoff_VlvSts: nonqueued-sender-com-spec{data-element=Value, init-value=CeRCVR_e_Vlv_Deenergize}, provided-interface=VeRCVR_e_HT_Shtoff_VlvSts
      VeRCVR_Pct_HT_CabVlvCmd: nonqueued-sender-com-spec{data-element=Value, init-value=0}, provided-interface=VeRCVR_Pct_HT_CabVlvCmd
      VeRCVR_Pct_HT_CabVlvSts: nonqueued-sender-com-spec{data-element=Value, init-value=0}, provided-interface=VeRCVR_Pct_HT_CabVlvSts
      VeRCVR_b_HT_CabVlvRely_Sts: nonqueued-sender-com-spec{data-element=Value, init-value=0}, provided-interface=VeRCVR_b_HT_CabVlvRely_Sts
      VeRCVR_b_HTCV_Learning_Req: nonqueued-sender-com-spec{data-element=Value, init-value=0}, provided-interface=VeRCVR_b_HTCV_Learning_Req
      VeRCVR_Pct_FrWyVlv_PstnCmnd: nonqueued-sender-com-spec{data-element=Value, init-value=0}, provided-interface=VeRCVR_Pct_FrWyVlv_PstnCmnd
      VeRCVR_e_FrWyVlv_CalCmnd: nonqueued-sender-com-spec{data-element=Value, init-value=CeRCVR_e_CPV_No_Calibration}, provided-interface=VeRCVR_e_FrWyVlv_CalCmnd
      VeRCVR_b_FrWyVlv_PstnSv: nonqueued-sender-com-spec{data-element=Value, init-value=0}, provided-interface=VeRCVR_b_FrWyVlv_PstnSv
      VeRCVR_e_CPV_RtnSts: nonqueued-sender-com-spec{data-element=Value, init-value=CeRCVR_e_CPV_RoutineSts_In_Progress}, provided-interface=VeRCVR_e_CPV_RtnSts
      VeRCVR_Pct_EXV_PosRq: nonqueued-sender-com-spec{data-element=Value, init-value=0}, provided-interface=VeRCVR_Pct_EXV_PosRq
      VeRCVR_e_EXV_CalCmd: nonqueued-sender-com-spec{data-element=Value, init-value=CeRCVR_e_EXV_No_Calibration}, provided-interface=VeRCVR_e_EXV_CalCmd
      VeRCVR_b_AC_ShtdwnRqst: nonqueued-sender-com-spec{data-element=Value, init-value=0}, provided-interface=VeRCVR_b_AC_ShtdwnRqst
      VeRCVR_b_Chlr_OpenCompTransition: nonqueued-sender-com-spec{data-element=Value, init-value=0}, provided-interface=VeRCVR_b_Chlr_OpenCompTransition
      VeRCVR_Pct_LTR_Vlv_PstnCmnd: nonqueued-sender-com-spec{data-element=Value, init-value=0}, provided-interface=VeRCVR_Pct_LTR_Vlv_PstnCmnd
      VeRCVR_e_LTR_Vlv_CalCmnd: nonqueued-sender-com-spec{data-element=Value, init-value=CeRCVR_e_CPV_No_Calibration}, provided-interface=VeRCVR_e_LTR_Vlv_CalCmnd
      VeRCVR_b_LTR_Vlv_PstnSv: nonqueued-sender-com-spec{data-element=Value, init-value=0}, provided-interface=VeRCVR_b_LTR_Vlv_PstnSv
      VeRCVR_Pct_HTL_Vlv_PstnCmnd: nonqueued-sender-com-spec{data-element=Value, init-value=0}, provided-interface=VeRCVR_Pct_HTL_Vlv_PstnCmnd
      VeRCVR_e_HTL_Vlv_CalCmnd: nonqueued-sender-com-spec{data-element=Value, init-value=CeRCVR_e_CPV_No_Calibration}, provided-interface=VeRCVR_e_HTL_Vlv_CalCmnd
      VeRCVR_b_HTL_Vlv_PstnSv: nonqueued-sender-com-spec{data-element=Value, init-value=0}, provided-interface=VeRCVR_b_HTL_Vlv_PstnSv
      VeRCVR_e_EXV_RtnSts: nonqueued-sender-com-spec{data-element=Value, init-value=CeRCVR_e_EXV_Routine_In_Progress}, provided-interface=VeRCVR_e_EXV_RtnSts
      VeRCVR_e_CPV_Valve_Stuck_State: nonqueued-sender-com-spec{data-element=Value, init-value=CeRCVR_e_Closed}, provided-interface=VeRCVR_e_CPV_Valve_Stuck_State
      VeRCVR_e_LTR_Valve_Stuck_State: nonqueued-sender-com-spec{data-element=Value, init-value=CeRCVR_e_Closed}, provided-interface=VeRCVR_e_LTR_Valve_Stuck_State
      VeRCVR_e_HTL_Valve_Stuck_State: nonqueued-sender-com-spec{data-element=Value, init-value=CeRCVR_e_Closed}, provided-interface=VeRCVR_e_HTL_Valve_Stuck_State
      VeRCVR_b_EXV_PresSensrRA: nonqueued-sender-com-spec{data-element=Value, init-value=0}, provided-interface=VeRCVR_b_EXV_PresSensrRA
      VeRCVR_b_RdyToShtDwn: nonqueued-sender-com-spec{data-element=Value, init-value=0}, provided-interface=VeRCVR_b_RdyToShtDwn
      VeRCVR_e_EEXV_CalRq: nonqueued-sender-com-spec{data-element=Value, init-value=CeRCVR_e_EXV_No_Calibration}, provided-interface=VeRCVR_e_EEXV_CalRq
      VeRCVR_Pct_EEXV_Cmd: nonqueued-sender-com-spec{data-element=Value, init-value=0}, provided-interface=VeRCVR_Pct_EEXV_Cmd
      VeRCVR_e_OEXV_CalRq: nonqueued-sender-com-spec{data-element=Value, init-value=CeRCVR_e_EXV_No_Calibration}, provided-interface=VeRCVR_e_OEXV_CalRq
      VeRCVR_Pct_OEXV_Cmd: nonqueued-sender-com-spec{data-element=Value, init-value=0}, provided-interface=VeRCVR_Pct_OEXV_Cmd
      VeRCVR_p_eACSuctionPressure: nonqueued-sender-com-spec{data-element=Value, init-value=0}, provided-interface=VeRCVR_p_eACSuctionPressure
      VeRCVR_Pct_HTR_Vlv_PstnCmnd: nonqueued-sender-com-spec{data-element=Value, init-value=0}, provided-interface=VeRCVR_Pct_HTR_Vlv_PstnCmnd
      VeRCVR_e_HTR_Vlv_CalCmnd: nonqueued-sender-com-spec{data-element=Value, init-value=CeRCVR_e_FCV_Allow_Normal_Operation}, provided-interface=VeRCVR_e_HTR_Vlv_CalCmnd
      VeRCVR_e_HTRBV_Block_Det_Enbl: nonqueued-sender-com-spec{data-element=Value, init-value=CeRCVR_e_FCV_False}, provided-interface=VeRCVR_e_HTRBV_Block_Det_Enbl
      VeRCVR_e_EEXV_RtnSts: nonqueued-sender-com-spec{data-element=Value, init-value=CeRCVR_e_EXV_Routine_In_Progress}, provided-interface=VeRCVR_e_EEXV_RtnSts
      VeRCVR_e_OEXV_RtnSts: nonqueued-sender-com-spec{data-element=Value, init-value=CeRCVR_e_EXV_Routine_In_Progress}, provided-interface=VeRCVR_e_OEXV_RtnSts
      VeRCVR_e_LTR_RtnSts: nonqueued-sender-com-spec{data-element=Value, init-value=CeRCVR_e_CPV_RoutineSts_In_Progress}, provided-interface=VeRCVR_e_LTR_RtnSts
      VeRCVR_e_HTL_RtnSts: nonqueued-sender-com-spec{data-element=Value, init-value=CeRCVR_e_CPV_RoutineSts_In_Progress}, provided-interface=VeRCVR_e_HTL_RtnSts
      VeRCVR_Pct_HtrCoreBypVlv_PstnCmnd: nonqueued-sender-com-spec{data-element=Value, init-value=0}, provided-interface=VeRCVR_Pct_HtrCoreBypVlv_PstnCmnd
      VeRCVR_e_HtrCoreBypVlv_CalCmnd: nonqueued-sender-com-spec{data-element=Value, init-value=CeRCVR_e_CPV_No_Calibration}, provided-interface=VeRCVR_e_HtrCoreBypVlv_CalCmnd
      VeRCVR_b_HtrCoreBypVlv_PstnSv: nonqueued-sender-com-spec{data-element=Value, init-value=0}, provided-interface=VeRCVR_b_HtrCoreBypVlv_PstnSv
      VeRCVR_e_HtrCoreBypVlv_Stuck_State: nonqueued-sender-com-spec{data-element=Value, init-value=CeRCVR_e_Closed}, provided-interface=VeRCVR_e_HtrCoreBypVlv_Stuck_State
      VeRCVR_Pct_CAC_BypVlv_PstnCmd: nonqueued-sender-com-spec{data-element=Value, init-value=0}, provided-interface=VeRCVR_Pct_CAC_BypVlv_PstnCmd
    11 x require port:
      EeRCVR_U_HT_CabVlvSts_Min_Rx: nv-require-com-spec{init-value=1.5, variable=EeRCVR_U_HT_CabVlvSts_Min}, required-interface=EeRCVR_U_HT_CabVlvSts_Min
      NeRCVR_Cnt_HTL_CntrlrShtDwn_Cycles_Rx: nv-require-com-spec{init-value=0, variable=NeRCVR_Cnt_HTL_CntrlrShtDwn_Cycles}, required-interface=NeRCVR_Cnt_HTL_CntrlrShtDwn_Cycles
      EeRCVR_Cnt_OEXV_CyclesSncCal_Rx: nv-require-com-spec{init-value=0, variable=EeRCVR_Cnt_OEXV_CyclesSncCal}, required-interface=EeRCVR_Cnt_OEXV_CyclesSncCal
      EeRCVR_U_HT_CabVlvSts_Max_Rx: nv-require-com-spec{init-value=3.4500000476837158, variable=EeRCVR_U_HT_CabVlvSts_Max}, required-interface=EeRCVR_U_HT_CabVlvSts_Max
      EeRCVR_Cnt_EEXV_CyclesSncCal_Rx: nv-require-com-spec{init-value=0, variable=EeRCVR_Cnt_EEXV_CyclesSncCal}, required-interface=EeRCVR_Cnt_EEXV_CyclesSncCal
      EeRCVR_Cnt_HTCV_Endstophits_Rx: nv-require-com-spec{init-value=5000, variable=EeRCVR_Cnt_HTCV_Endstophits}, required-interface=EeRCVR_Cnt_HTCV_Endstophits
      EeRCVR_e_HTCV_Calibration_Sts_Rx: nv-require-com-spec{init-value=255, variable=EeRCVR_e_HTCV_Calibration_Sts}, required-interface=EeRCVR_e_HTCV_Calibration_Sts
      NeRCVR_Cnt_CPV_CntrlrShtDwn_Cycles_Rx: nv-require-com-spec{init-value=0, variable=NeRCVR_Cnt_CPV_CntrlrShtDwn_Cycles}, required-interface=NeRCVR_Cnt_CPV_CntrlrShtDwn_Cycles
      EeRCVR_Cnt_EXV_CyclesSncCal_Rx: nv-require-com-spec{init-value=0, variable=EeRCVR_Cnt_EXV_CyclesSncCal}, required-interface=EeRCVR_Cnt_EXV_CyclesSncCal
      NeRCVR_Cnt_LTR_CntrlrShtDwn_Cycles_Rx: nv-require-com-spec{init-value=0, variable=NeRCVR_Cnt_LTR_CntrlrShtDwn_Cycles}, required-interface=NeRCVR_Cnt_LTR_CntrlrShtDwn_Cycles
      NeRCVR_Cnt_HtrCore_CntrlrShtDwn_Cycles_Rx: nv-require-com-spec{init-value=0, variable=NeRCVR_Cnt_HtrCore_CntrlrShtDwn_Cycles}, required-interface=NeRCVR_Cnt_HtrCore_CntrlrShtDwn_Cycles
    11 x provide port:
      EeRCVR_U_HT_CabVlvSts_Min: nv-provide-com-spec{ram-block-init-value=1.5, variable=EeRCVR_U_HT_CabVlvSts_Min}, provided-interface=EeRCVR_U_HT_CabVlvSts_Min
      NeRCVR_Cnt_HTL_CntrlrShtDwn_Cycles: nv-provide-com-spec{ram-block-init-value=0, variable=NeRCVR_Cnt_HTL_CntrlrShtDwn_Cycles}, provided-interface=NeRCVR_Cnt_HTL_CntrlrShtDwn_Cycles
      EeRCVR_Cnt_OEXV_CyclesSncCal: nv-provide-com-spec{ram-block-init-value=0, variable=EeRCVR_Cnt_OEXV_CyclesSncCal}, provided-interface=EeRCVR_Cnt_OEXV_CyclesSncCal
      EeRCVR_U_HT_CabVlvSts_Max: nv-provide-com-spec{ram-block-init-value=3.4500000476837158, variable=EeRCVR_U_HT_CabVlvSts_Max}, provided-interface=EeRCVR_U_HT_CabVlvSts_Max
      EeRCVR_Cnt_EEXV_CyclesSncCal: nv-provide-com-spec{ram-block-init-value=0, variable=EeRCVR_Cnt_EEXV_CyclesSncCal}, provided-interface=EeRCVR_Cnt_EEXV_CyclesSncCal
      EeRCVR_Cnt_HTCV_Endstophits: nv-provide-com-spec{ram-block-init-value=5000, variable=EeRCVR_Cnt_HTCV_Endstophits}, provided-interface=EeRCVR_Cnt_HTCV_Endstophits
      EeRCVR_e_HTCV_Calibration_Sts: nv-provide-com-spec{ram-block-init-value=255, variable=EeRCVR_e_HTCV_Calibration_Sts}, provided-interface=EeRCVR_e_HTCV_Calibration_Sts
      NeRCVR_Cnt_CPV_CntrlrShtDwn_Cycles: nv-provide-com-spec{ram-block-init-value=0, variable=NeRCVR_Cnt_CPV_CntrlrShtDwn_Cycles}, provided-interface=NeRCVR_Cnt_CPV_CntrlrShtDwn_Cycles
      EeRCVR_Cnt_EXV_CyclesSncCal: nv-provide-com-spec{ram-block-init-value=0, variable=EeRCVR_Cnt_EXV_CyclesSncCal}, provided-interface=EeRCVR_Cnt_EXV_CyclesSncCal
      NeRCVR_Cnt_LTR_CntrlrShtDwn_Cycles: nv-provide-com-spec{ram-block-init-value=0, variable=NeRCVR_Cnt_LTR_CntrlrShtDwn_Cycles}, provided-interface=NeRCVR_Cnt_LTR_CntrlrShtDwn_Cycles
      NeRCVR_Cnt_HtrCore_CntrlrShtDwn_Cycles: nv-provide-com-spec{ram-block-init-value=0, variable=NeRCVR_Cnt_HtrCore_CntrlrShtDwn_Cycles}, provided-interface=NeRCVR_Cnt_HtrCore_CntrlrShtDwn_Cycles
    behavior IB_RCVR: data-type-mapping=msADTtoIDTMapping, handle-termination-and-restart=NO-SUPPORT, included-data-type-set=data-type=[TeRCVR_e_CPV_States, TeRCVR_e_FCV_States, TeRCVR_e_HT_CabVlvState]
      timing event Event_MedTED: start-on-event=RCVR_MedTED, period=0.02
      init event Event_RCVR_ac_Init: start-on-event=RCVR_ac_Init
      init event Event_PwrOn: start-on-event=RCVR_PwrOn
      init event Event_PwrOff: start-on-event=RCVR_PwrOff
      data received event Event_Routine_RC1309_CPV_ClbrtnRtn: start-on-event=Routine_RC1309_CPV_ClbrtnRtn, data=VeDCAB_e_Routine_RC1309_CPV_ClbrtnRtn_Op.Value
      data received event Event_Routine_RC130E_LTR_ClbrtnRtn: start-on-event=Routine_RC130E_LTR_ClbrtnRtn, data=VeDCAB_e_Routine_RC130E_LTR_ClbrtnRtn_Op.Value
      data received event Event_Routine_RC130F_HTL_ClbrtnRtn: start-on-event=Routine_RC130F_HTL_ClbrtnRtn, data=VeDCAB_e_Routine_RC130F_HTL_ClbrtnRtn_Op.Value
      7 x runnable:
        RCVR_ac_Init
          data-send-points:
            20 x access:
              OUT_VeRCVR_e_HT_Shtoff_VlvSts_Value: accessed-variable=VeRCVR_e_HT_Shtoff_VlvSts.Value
              OUT_VeRCVR_e_FrWyVlv_CalCmnd_Value: accessed-variable=VeRCVR_e_FrWyVlv_CalCmnd.Value
              OUT_VeRCVR_e_CPV_RtnSts_Value: accessed-variable=VeRCVR_e_CPV_RtnSts.Value
              OUT_VeRCVR_e_EXV_CalCmd_Value: accessed-variable=VeRCVR_e_EXV_CalCmd.Value
              OUT_VeRCVR_e_LTR_Vlv_CalCmnd_Value: accessed-variable=VeRCVR_e_LTR_Vlv_CalCmnd.Value
              OUT_VeRCVR_e_HTL_Vlv_CalCmnd_Value: accessed-variable=VeRCVR_e_HTL_Vlv_CalCmnd.Value
              OUT_VeRCVR_e_EXV_RtnSts_Value: accessed-variable=VeRCVR_e_EXV_RtnSts.Value
              OUT_VeRCVR_e_CPV_Valve_Stuck_State_Value: accessed-variable=VeRCVR_e_CPV_Valve_Stuck_State.Value
              OUT_VeRCVR_e_LTR_Valve_Stuck_State_Value: accessed-variable=VeRCVR_e_LTR_Valve_Stuck_State.Value
              OUT_VeRCVR_e_HTL_Valve_Stuck_State_Value: accessed-variable=VeRCVR_e_HTL_Valve_Stuck_State.Value
              OUT_VeRCVR_e_EEXV_CalRq_Value: accessed-variable=VeRCVR_e_EEXV_CalRq.Value
              OUT_VeRCVR_e_OEXV_CalRq_Value: accessed-variable=VeRCVR_e_OEXV_CalRq.Value
              OUT_VeRCVR_e_HTR_Vlv_CalCmnd_Value: accessed-variable=VeRCVR_e_HTR_Vlv_CalCmnd.Value
              OUT_VeRCVR_e_HTRBV_Block_Det_Enbl_Value: accessed-variable=VeRCVR_e_HTRBV_Block_Det_Enbl.Value
              OUT_VeRCVR_e_EEXV_RtnSts_Value: accessed-variable=VeRCVR_e_EEXV_RtnSts.Value
              OUT_VeRCVR_e_OEXV_RtnSts_Value: accessed-variable=VeRCVR_e_OEXV_RtnSts.Value
              OUT_VeRCVR_e_LTR_RtnSts_Value: accessed-variable=VeRCVR_e_LTR_RtnSts.Value
              OUT_VeRCVR_e_HTL_RtnSts_Value: accessed-variable=VeRCVR_e_HTL_RtnSts.Value
              OUT_VeRCVR_e_HtrCoreBypVlv_CalCmnd_Value: accessed-variable=VeRCVR_e_HtrCoreBypVlv_CalCmnd.Value
              OUT_VeRCVR_e_HtrCoreBypVlv_Stuck_State_Value: accessed-variable=VeRCVR_e_HtrCoreBypVlv_Stuck_State.Value
        RCVR_PwrOn
          data-receive-point-by-arguments:
            11 x access:
              IN_EeRCVR_Cnt_EEXV_CyclesSncCal_Rx_EeRCVR_Cnt_EEXV_CyclesSncCal: accessed-variable=EeRCVR_Cnt_EEXV_CyclesSncCal_Rx.EeRCVR_Cnt_EEXV_CyclesSncCal
              IN_EeRCVR_Cnt_EXV_CyclesSncCal_Rx_EeRCVR_Cnt_EXV_CyclesSncCal: accessed-variable=EeRCVR_Cnt_EXV_CyclesSncCal_Rx.EeRCVR_Cnt_EXV_CyclesSncCal
              IN_EeRCVR_Cnt_HTCV_Endstophits_Rx_EeRCVR_Cnt_HTCV_Endstophits: accessed-variable=EeRCVR_Cnt_HTCV_Endstophits_Rx.EeRCVR_Cnt_HTCV_Endstophits
              IN_EeRCVR_Cnt_OEXV_CyclesSncCal_Rx_EeRCVR_Cnt_OEXV_CyclesSncCal: accessed-variable=EeRCVR_Cnt_OEXV_CyclesSncCal_Rx.EeRCVR_Cnt_OEXV_CyclesSncCal
              IN_EeRCVR_U_HT_CabVlvSts_Max_Rx_EeRCVR_U_HT_CabVlvSts_Max: accessed-variable=EeRCVR_U_HT_CabVlvSts_Max_Rx.EeRCVR_U_HT_CabVlvSts_Max
              IN_EeRCVR_U_HT_CabVlvSts_Min_Rx_EeRCVR_U_HT_CabVlvSts_Min: accessed-variable=EeRCVR_U_HT_CabVlvSts_Min_Rx.EeRCVR_U_HT_CabVlvSts_Min
              IN_EeRCVR_e_HTCV_Calibration_Sts_Rx_EeRCVR_e_HTCV_Calibration_Sts: accessed-variable=EeRCVR_e_HTCV_Calibration_Sts_Rx.EeRCVR_e_HTCV_Calibration_Sts
              IN_NeRCVR_Cnt_CPV_CntrlrShtDwn_Cycles_Rx_NeRCVR_Cnt_CPV_CntrlrShtDwn_Cycles: accessed-variable=NeRCVR_Cnt_CPV_CntrlrShtDwn_Cycles_Rx.NeRCVR_Cnt_CPV_CntrlrShtDwn_Cycles
              IN_NeRCVR_Cnt_HTL_CntrlrShtDwn_Cycles_Rx_NeRCVR_Cnt_HTL_CntrlrShtDwn_Cycles: accessed-variable=NeRCVR_Cnt_HTL_CntrlrShtDwn_Cycles_Rx.NeRCVR_Cnt_HTL_CntrlrShtDwn_Cycles
              IN_NeRCVR_Cnt_HtrCore_CntrlrShtDwn_Cycles_Rx_NeRCVR_Cnt_HtrCore_CntrlrShtDwn_Cycles: accessed-variable=NeRCVR_Cnt_HtrCore_CntrlrShtDwn_Cycles_Rx.NeRCVR_Cnt_HtrCore_CntrlrShtDwn_Cycles
              IN_NeRCVR_Cnt_LTR_CntrlrShtDwn_Cycles_Rx_NeRCVR_Cnt_LTR_CntrlrShtDwn_Cycles: accessed-variable=NeRCVR_Cnt_LTR_CntrlrShtDwn_Cycles_Rx.NeRCVR_Cnt_LTR_CntrlrShtDwn_Cycles
          data-send-points:
            49 x access:
              OUT_VeRCVR_b_FtRfgtShtoff_VlvCmd_Value: accessed-variable=VeRCVR_b_FtRfgtShtoff_VlvCmd.Value
              OUT_VeRCVR_b_FtRfgtShtoff_VlvSts_Value: accessed-variable=VeRCVR_b_FtRfgtShtoff_VlvSts.Value
              OUT_VeRCVR_b_HT_CabVlvRely_Sts_Value: accessed-variable=VeRCVR_b_HT_CabVlvRely_Sts.Value
              OUT_VeRCVR_b_HTCV_Learning_Req_Value: accessed-variable=VeRCVR_b_HTCV_Learning_Req.Value
              OUT_VeRCVR_Pct_FrWyVlv_PstnCmnd_Value: accessed-variable=VeRCVR_Pct_FrWyVlv_PstnCmnd.Value
              OUT_VeRCVR_e_FrWyVlv_CalCmnd_Value: accessed-variable=VeRCVR_e_FrWyVlv_CalCmnd.Value
              OUT_VeRCVR_b_FrWyVlv_PstnSv_Value: accessed-variable=VeRCVR_b_FrWyVlv_PstnSv.Value
              OUT_VeRCVR_e_CPV_RtnSts_Value: accessed-variable=VeRCVR_e_CPV_RtnSts.Value
              OUT_VeRCVR_Pct_EXV_PosRq_Value: accessed-variable=VeRCVR_Pct_EXV_PosRq.Value
              OUT_VeRCVR_e_EXV_CalCmd_Value: accessed-variable=VeRCVR_e_EXV_CalCmd.Value
              OUT_VeRCVR_b_AC_ShtdwnRqst_Value: accessed-variable=VeRCVR_b_AC_ShtdwnRqst.Value
              OUT_VeRCVR_b_Chlr_OpenCompTransition_Value: accessed-variable=VeRCVR_b_Chlr_OpenCompTransition.Value
              OUT_VeRCVR_b_RSVCompTransition_Value: accessed-variable=VeRCVR_b_RSVCompTransition.Value
              OUT_VeRCVR_Pct_LTR_Vlv_PstnCmnd_Value: accessed-variable=VeRCVR_Pct_LTR_Vlv_PstnCmnd.Value
              OUT_VeRCVR_e_LTR_Vlv_CalCmnd_Value: accessed-variable=VeRCVR_e_LTR_Vlv_CalCmnd.Value
              OUT_VeRCVR_b_LTR_Vlv_PstnSv_Value: accessed-variable=VeRCVR_b_LTR_Vlv_PstnSv.Value
              OUT_VeRCVR_Pct_HTL_Vlv_PstnCmnd_Value: accessed-variable=VeRCVR_Pct_HTL_Vlv_PstnCmnd.Value
              OUT_VeRCVR_e_HTL_Vlv_CalCmnd_Value: accessed-variable=VeRCVR_e_HTL_Vlv_CalCmnd.Value
              OUT_VeRCVR_b_HTL_Vlv_PstnSv_Value: accessed-variable=VeRCVR_b_HTL_Vlv_PstnSv.Value
              OUT_VeRCVR_e_EXV_RtnSts_Value: accessed-variable=VeRCVR_e_EXV_RtnSts.Value
              OUT_VeRCVR_e_CPV_Valve_Stuck_State_Value: accessed-variable=VeRCVR_e_CPV_Valve_Stuck_State.Value
              OUT_VeRCVR_e_LTR_Valve_Stuck_State_Value: accessed-variable=VeRCVR_e_LTR_Valve_Stuck_State.Value
              OUT_VeRCVR_e_HTL_Valve_Stuck_State_Value: accessed-variable=VeRCVR_e_HTL_Valve_Stuck_State.Value
              OUT_VeRCVR_b_ChlrRfgtShtoff_VlvCmd_Value: accessed-variable=VeRCVR_b_ChlrRfgtShtoff_VlvCmd.Value
              OUT_VeRCVR_b_EXV_PresSensrRA_Value: accessed-variable=VeRCVR_b_EXV_PresSensrRA.Value
              OUT_VeRCVR_b_RdyToShtDwn_Value: accessed-variable=VeRCVR_b_RdyToShtDwn.Value
              OUT_VeRCVR_e_EEXV_CalRq_Value: accessed-variable=VeRCVR_e_EEXV_CalRq.Value
              OUT_VeRCVR_Pct_EEXV_Cmd_Value: accessed-variable=VeRCVR_Pct_EEXV_Cmd.Value
              OUT_VeRCVR_e_OEXV_CalRq_Value: accessed-variable=VeRCVR_e_OEXV_CalRq.Value
              OUT_VeRCVR_Pct_OEXV_Cmd_Value: accessed-variable=VeRCVR_Pct_OEXV_Cmd.Value
              OUT_VeRCVR_p_eACSuctionPressure_Value: accessed-variable=VeRCVR_p_eACSuctionPressure.Value
              OUT_VeRCVR_Pct_HTR_Vlv_PstnCmnd_Value: accessed-variable=VeRCVR_Pct_HTR_Vlv_PstnCmnd.Value
              OUT_VeRCVR_e_HTR_Vlv_CalCmnd_Value: accessed-variable=VeRCVR_e_HTR_Vlv_CalCmnd.Value
              OUT_VeRCVR_e_HTRBV_Block_Det_Enbl_Value: accessed-variable=VeRCVR_e_HTRBV_Block_Det_Enbl.Value
              OUT_VeRCVR_b_ChlrRfrgtShtoff_VlvSts_Value: accessed-variable=VeRCVR_b_ChlrRfrgtShtoff_VlvSts.Value
              OUT_VeRCVR_b_HT_Shtoff_VlvCmd_Value: accessed-variable=VeRCVR_b_HT_Shtoff_VlvCmd.Value
              OUT_VeRCVR_b_HT_Shtoff_VlvSts_Value: accessed-variable=VeRCVR_b_HT_Shtoff_VlvSts.Value
              OUT_VeRCVR_e_HT_Shtoff_VlvSts_Value: accessed-variable=VeRCVR_e_HT_Shtoff_VlvSts.Value
              OUT_VeRCVR_Pct_HT_CabVlvCmd_Value: accessed-variable=VeRCVR_Pct_HT_CabVlvCmd.Value
              OUT_VeRCVR_Pct_HT_CabVlvSts_Value: accessed-variable=VeRCVR_Pct_HT_CabVlvSts.Value
              OUT_VeRCVR_e_EEXV_RtnSts_Value: accessed-variable=VeRCVR_e_EEXV_RtnSts.Value
              OUT_VeRCVR_e_OEXV_RtnSts_Value: accessed-variable=VeRCVR_e_OEXV_RtnSts.Value
              OUT_VeRCVR_e_LTR_RtnSts_Value: accessed-variable=VeRCVR_e_LTR_RtnSts.Value
              OUT_VeRCVR_e_HTL_RtnSts_Value: accessed-variable=VeRCVR_e_HTL_RtnSts.Value
              OUT_VeRCVR_Pct_HtrCoreBypVlv_PstnCmnd_Value: accessed-variable=VeRCVR_Pct_HtrCoreBypVlv_PstnCmnd.Value
              OUT_VeRCVR_e_HtrCoreBypVlv_CalCmnd_Value: accessed-variable=VeRCVR_e_HtrCoreBypVlv_CalCmnd.Value
              OUT_VeRCVR_b_HtrCoreBypVlv_PstnSv_Value: accessed-variable=VeRCVR_b_HtrCoreBypVlv_PstnSv.Value
              OUT_VeRCVR_e_HtrCoreBypVlv_Stuck_State_Value: accessed-variable=VeRCVR_e_HtrCoreBypVlv_Stuck_State.Value
              OUT_VeRCVR_Pct_CAC_BypVlv_PstnCmd_Value: accessed-variable=VeRCVR_Pct_CAC_BypVlv_PstnCmd.Value
        RCVR_MedTED: variation-point={short-label=vpRCVR_MedTED, sw-syscond=1}
          data-receive-point-by-arguments:
            153 x access:
              IN_VeAATR_T_EstAmbAirTemp_Value: accessed-variable=VeAATR_T_EstAmbAirTemp.Value, variation-point={short-label=vpIN_VeAATR_T_EstAmbAirTemp_Value, sw-syscond=1}
              IN_VeAATR_b_EstAmbAirTempFA_Value: accessed-variable=VeAATR_b_EstAmbAirTempFA.Value, variation-point={short-label=vpIN_VeAATR_b_EstAmbAirTempFA_Value, sw-syscond=1}
              IN_VeACCR_b_OilMigOpnVlv_Value: accessed-variable=VeACCR_b_OilMigOpnVlv.Value, variation-point={short-label=vpIN_VeACCR_b_OilMigOpnVlv_Value, sw-syscond=1}
              IN_VeACCR_n_ChillerV_OpenMaxRPM_Value: accessed-variable=VeACCR_n_ChillerV_OpenMaxRPM.Value, variation-point={short-label=vpIN_VeACCR_n_ChillerV_OpenMaxRPM_Value, sw-syscond=1}
              IN_VeACCR_n_FtERV_ShutMaxRPM_Value: accessed-variable=VeACCR_n_FtERV_ShutMaxRPM.Value, variation-point={short-label=vpIN_VeACCR_n_FtERV_ShutMaxRPM_Value, sw-syscond=1}
              IN_VeBSWR_b_LimCheckingStatus_Value: accessed-variable=VeBSWR_b_LimCheckingStatus.Value, variation-point={short-label=vpIN_VeBSWR_b_LimCheckingStatus_Value, sw-syscond=1}
              IN_VeBTRR_dT_CellOverTemp_Value: accessed-variable=VeBTRR_dT_CellOverTemp.Value, variation-point={short-label=vpIN_VeBTRR_dT_CellOverTemp_Value, sw-syscond=1}
              IN_VeCITR_e_FOTA_Install_Type_Value: accessed-variable=VeCITR_e_FOTA_Install_Type.Value, variation-point={short-label=vpIN_VeCITR_e_FOTA_Install_Type_Value, sw-syscond=1}
              IN_VeDMAB_y_StatusByte_AC_RefrigExpVlvActD_CntrlCktPerf_Value: accessed-variable=VeDMAB_y_StatusByte_AC_RefrigExpVlvActD_CntrlCktPerf.Value, variation-point={short-label=vpIN_VeDMAB_y_StatusByte_AC_RefrigExpVlvActD_CntrlCktPerf_Value, sw-syscond=1}
              IN_VeDMAB_y_StatusByte_AC_RefrigExpVlvAct_C_CntrlCktPerf_Value: accessed-variable=VeDMAB_y_StatusByte_AC_RefrigExpVlvAct_C_CntrlCktPerf.Value, variation-point={short-label=vpIN_VeDMAB_y_StatusByte_AC_RefrigExpVlvAct_C_CntrlCktPerf_Value, sw-syscond=1}
              IN_VeDMAB_y_StatusByte_AC_RefrigPresSnsrAHi_Value: accessed-variable=VeDMAB_y_StatusByte_AC_RefrigPresSnsrAHi.Value, variation-point={short-label=vpIN_VeDMAB_y_StatusByte_AC_RefrigPresSnsrAHi_Value, sw-syscond=1}
              IN_VeDMAB_y_StatusByte_AC_RefrigPresSnsrALo_Value: accessed-variable=VeDMAB_y_StatusByte_AC_RefrigPresSnsrALo.Value, variation-point={short-label=vpIN_VeDMAB_y_StatusByte_AC_RefrigPresSnsrALo_Value, sw-syscond=1}
              IN_VeDMAB_y_StatusByte_AC_RefrigPresSnsrAPerf_Value: accessed-variable=VeDMAB_y_StatusByte_AC_RefrigPresSnsrAPerf.Value, variation-point={short-label=vpIN_VeDMAB_y_StatusByte_AC_RefrigPresSnsrAPerf_Value, sw-syscond=1}
              IN_VeDMAB_y_StatusByte_AC_RefrigPresSnsrCCkt_Value: accessed-variable=VeDMAB_y_StatusByte_AC_RefrigPresSnsrCCkt.Value, variation-point={short-label=vpIN_VeDMAB_y_StatusByte_AC_RefrigPresSnsrCCkt_Value, sw-syscond=1}
              IN_VeDMAB_y_StatusByte_AC_RefrigPresSnsrCCktPerf_Value: accessed-variable=VeDMAB_y_StatusByte_AC_RefrigPresSnsrCCktPerf.Value, variation-point={short-label=vpIN_VeDMAB_y_StatusByte_AC_RefrigPresSnsrCCktPerf_Value, sw-syscond=1}
              IN_VeDMAB_y_StatusByte_AC_RefrigPresSnsrDCkt_Value: accessed-variable=VeDMAB_y_StatusByte_AC_RefrigPresSnsrDCkt.Value, variation-point={short-label=vpIN_VeDMAB_y_StatusByte_AC_RefrigPresSnsrDCkt_Value, sw-syscond=1}
              IN_VeDMAB_y_StatusByte_AC_RefrigPresSnsrDCktPerf_Value: accessed-variable=VeDMAB_y_StatusByte_AC_RefrigPresSnsrDCktPerf.Value, variation-point={short-label=vpIN_VeDMAB_y_StatusByte_AC_RefrigPresSnsrDCktPerf_Value, sw-syscond=1}
              IN_VeDMAB_y_StatusByte_AC_RefrigTempSnsr4CktPerf_Value: accessed-variable=VeDMAB_y_StatusByte_AC_RefrigTempSnsr4CktPerf.Value, variation-point={short-label=vpIN_VeDMAB_y_StatusByte_AC_RefrigTempSnsr4CktPerf_Value, sw-syscond=1}
              IN_VeDMAB_y_StatusByte_AC_RefrigTempSnsr5CktPerf_Value: accessed-variable=VeDMAB_y_StatusByte_AC_RefrigTempSnsr5CktPerf.Value, variation-point={short-label=vpIN_VeDMAB_y_StatusByte_AC_RefrigTempSnsr5CktPerf_Value, sw-syscond=1}
              IN_VeDMAB_y_StatusByte_AC_RefrigTempSnsr5CktShotoBat_Value: accessed-variable=VeDMAB_y_StatusByte_AC_RefrigTempSnsr5CktShotoBat.Value, variation-point={short-label=vpIN_VeDMAB_y_StatusByte_AC_RefrigTempSnsr5CktShotoBat_Value, sw-syscond=1}
              IN_VeDMAB_y_StatusByte_AC_RefrigTempSnsr5CktShotoGro_Value: accessed-variable=VeDMAB_y_StatusByte_AC_RefrigTempSnsr5CktShotoGro.Value, variation-point={short-label=vpIN_VeDMAB_y_StatusByte_AC_RefrigTempSnsr5CktShotoGro_Value, sw-syscond=1}
              IN_VeDMAB_y_StatusByte_AC_RefrigTempSnsrACkt_Value: accessed-variable=VeDMAB_y_StatusByte_AC_RefrigTempSnsrACkt.Value, variation-point={short-label=vpIN_VeDMAB_y_StatusByte_AC_RefrigTempSnsrACkt_Value, sw-syscond=1}
              IN_VeDMAB_y_StatusByte_AC_RefrigTempSnsrAPerf_Value: accessed-variable=VeDMAB_y_StatusByte_AC_RefrigTempSnsrAPerf.Value, variation-point={short-label=vpIN_VeDMAB_y_StatusByte_AC_RefrigTempSnsrAPerf_Value, sw-syscond=1}
              IN_VeDMAB_y_StatusByte_AC_RefrigTempSnsrBCkt_Value: accessed-variable=VeDMAB_y_StatusByte_AC_RefrigTempSnsrBCkt.Value, variation-point={short-label=vpIN_VeDMAB_y_StatusByte_AC_RefrigTempSnsrBCkt_Value, sw-syscond=1}
              IN_VeDMAB_y_StatusByte_AC_RefrigTempSnsrBPerf_Value: accessed-variable=VeDMAB_y_StatusByte_AC_RefrigTempSnsrBPerf.Value, variation-point={short-label=vpIN_VeDMAB_y_StatusByte_AC_RefrigTempSnsrBPerf_Value, sw-syscond=1}
              IN_VeDMAB_y_StatusByte_AC_RefrigTempSnsrCCkt_Value: accessed-variable=VeDMAB_y_StatusByte_AC_RefrigTempSnsrCCkt.Value, variation-point={short-label=vpIN_VeDMAB_y_StatusByte_AC_RefrigTempSnsrCCkt_Value, sw-syscond=1}
              IN_VeDMAB_y_StatusByte_AC_RefrigTempSnsrCPerf_Value: accessed-variable=VeDMAB_y_StatusByte_AC_RefrigTempSnsrCPerf.Value, variation-point={short-label=vpIN_VeDMAB_y_StatusByte_AC_RefrigTempSnsrCPerf_Value, sw-syscond=1}
              IN_VeDMAB_y_StatusByte_AC_RefrigTempSnsrDCkt_Value: accessed-variable=VeDMAB_y_StatusByte_AC_RefrigTempSnsrDCkt.Value, variation-point={short-label=vpIN_VeDMAB_y_StatusByte_AC_RefrigTempSnsrDCkt_Value, sw-syscond=1}
              IN_VeDMAB_y_StatusByte_CoolCtrlVlv1Ckt_Value: accessed-variable=VeDMAB_y_StatusByte_CoolCtrlVlv1Ckt.Value, variation-point={short-label=vpIN_VeDMAB_y_StatusByte_CoolCtrlVlv1Ckt_Value, sw-syscond=1}
              IN_VeDMAB_y_StatusByte_CoolCtrlVlv1CktHi_Value: accessed-variable=VeDMAB_y_StatusByte_CoolCtrlVlv1CktHi.Value, variation-point={short-label=vpIN_VeDMAB_y_StatusByte_CoolCtrlVlv1CktHi_Value, sw-syscond=1}
              IN_VeDMAB_y_StatusByte_CoolCtrlVlv1CktLo_Value: accessed-variable=VeDMAB_y_StatusByte_CoolCtrlVlv1CktLo.Value, variation-point={short-label=vpIN_VeDMAB_y_StatusByte_CoolCtrlVlv1CktLo_Value, sw-syscond=1}
              IN_VeDMAB_y_StatusByte_CoolantVlvA_Ckt_Value: accessed-variable=VeDMAB_y_StatusByte_CoolantVlvA_Ckt.Value, variation-point={short-label=vpIN_VeDMAB_y_StatusByte_CoolantVlvA_Ckt_Value, sw-syscond=1}
              IN_VeDMAB_y_StatusByte_CoolantVlvA_CktHi_Value: accessed-variable=VeDMAB_y_StatusByte_CoolantVlvA_CktHi.Value, variation-point={short-label=vpIN_VeDMAB_y_StatusByte_CoolantVlvA_CktHi_Value, sw-syscond=1}
              IN_VeDMAB_y_StatusByte_CoolantVlvA_CktLo_Value: accessed-variable=VeDMAB_y_StatusByte_CoolantVlvA_CktLo.Value, variation-point={short-label=vpIN_VeDMAB_y_StatusByte_CoolantVlvA_CktLo_Value, sw-syscond=1}
              IN_VeDMAB_y_StatusByte_CoolantVlvB_Ckt_Value: accessed-variable=VeDMAB_y_StatusByte_CoolantVlvB_Ckt.Value, variation-point={short-label=vpIN_VeDMAB_y_StatusByte_CoolantVlvB_Ckt_Value, sw-syscond=1}
              IN_VeDMAB_y_StatusByte_CoolantVlvB_CktHi_Value: accessed-variable=VeDMAB_y_StatusByte_CoolantVlvB_CktHi.Value, variation-point={short-label=vpIN_VeDMAB_y_StatusByte_CoolantVlvB_CktHi_Value, sw-syscond=1}
              IN_VeDMAB_y_StatusByte_EvapRefriShutoffCtrlCktFlt_Value: accessed-variable=VeDMAB_y_StatusByte_EvapRefriShutoffCtrlCktFlt.Value, variation-point={short-label=vpIN_VeDMAB_y_StatusByte_EvapRefriShutoffCtrlCktFlt_Value, sw-syscond=1}
              IN_VeDMAB_y_StatusByte_EvapRefriShutoffCtrlshrtBattFlt_Value: accessed-variable=VeDMAB_y_StatusByte_EvapRefriShutoffCtrlshrtBattFlt.Value, variation-point={short-label=vpIN_VeDMAB_y_StatusByte_EvapRefriShutoffCtrlshrtBattFlt_Value, sw-syscond=1}
              IN_VeDMAB_y_StatusByte_EvapRefrishutoffCtrlShrtGndFlt_Value: accessed-variable=VeDMAB_y_StatusByte_EvapRefrishutoffCtrlShrtGndFlt.Value, variation-point={short-label=vpIN_VeDMAB_y_StatusByte_EvapRefrishutoffCtrlShrtGndFlt_Value, sw-syscond=1}
              IN_VeDMAB_y_StatusByte_HB_PSC_CtrlValACktPerf_Value: accessed-variable=VeDMAB_y_StatusByte_HB_PSC_CtrlValACktPerf.Value, variation-point={short-label=vpIN_VeDMAB_y_StatusByte_HB_PSC_CtrlValACktPerf_Value, sw-syscond=1}
              IN_VeDMAB_y_StatusByte_HB_PSC_CtrlValBCktPerf_Value: accessed-variable=VeDMAB_y_StatusByte_HB_PSC_CtrlValBCktPerf.Value, variation-point={short-label=vpIN_VeDMAB_y_StatusByte_HB_PSC_CtrlValBCktPerf_Value, sw-syscond=1}
              IN_VeDMAB_y_StatusByte_HB_PSC_CtrlValCCktPerf_Value: accessed-variable=VeDMAB_y_StatusByte_HB_PSC_CtrlValCCktPerf.Value, variation-point={short-label=vpIN_VeDMAB_y_StatusByte_HB_PSC_CtrlValCCktPerf_Value, sw-syscond=1}
              IN_VeDMAB_y_StatusByte_LIN{1..3}_BusOff_Value: accessed-variable=VeDMAB_y_StatusByte_LIN{1..3}_BusOff.Value, variation-point={short-label=vpIN_VeDMAB_y_StatusByte_LIN{1..3}_BusOff_Value, sw-syscond=1}
              IN_VeDMAB_y_StatusByte_LosCommHybPSCCtrlValA_Value: accessed-variable=VeDMAB_y_StatusByte_LosCommHybPSCCtrlValA.Value, variation-point={short-label=vpIN_VeDMAB_y_StatusByte_LosCommHybPSCCtrlValA_Value, sw-syscond=1}
              IN_VeDMAB_y_StatusByte_LostCommACRefrigExpVlvActA_Value: accessed-variable=VeDMAB_y_StatusByte_LostCommACRefrigExpVlvActA.Value, variation-point={short-label=vpIN_VeDMAB_y_StatusByte_LostCommACRefrigExpVlvActA_Value, sw-syscond=1}
              IN_VeDMAB_y_StatusByte_LostCommACRefrigExpVlvActC_Value: accessed-variable=VeDMAB_y_StatusByte_LostCommACRefrigExpVlvActC.Value, variation-point={short-label=vpIN_VeDMAB_y_StatusByte_LostCommACRefrigExpVlvActC_Value, sw-syscond=1}
              IN_VeDMAB_y_StatusByte_LostCommHB_PSCCooCtrlVlvB_Value: accessed-variable=VeDMAB_y_StatusByte_LostCommHB_PSCCooCtrlVlvB.Value, variation-point={short-label=vpIN_VeDMAB_y_StatusByte_LostCommHB_PSCCooCtrlVlvB_Value, sw-syscond=1}
              IN_VeDMAB_y_StatusByte_LostCommHB_PSCCooCtrlVlvC_Value: accessed-variable=VeDMAB_y_StatusByte_LostCommHB_PSCCooCtrlVlvC.Value, variation-point={short-label=vpIN_VeDMAB_y_StatusByte_LostCommHB_PSCCooCtrlVlvC_Value, sw-syscond=1}
              IN_VePDTR_e_EngOrBattPwrDschg_State_Value: accessed-variable=VePDTR_e_EngOrBattPwrDschg_State.Value, variation-point={short-label=vpIN_VePDTR_e_EngOrBattPwrDschg_State_Value, sw-syscond=1}
              IN_VePLTR_b_InFieldMode_Value: accessed-variable=VePLTR_b_InFieldMode.Value, variation-point={short-label=vpIN_VePLTR_b_InFieldMode_Value, sw-syscond=1}
              IN_VePMDR_e_PMM_PowerMode_Value: accessed-variable=VePMDR_e_PMM_PowerMode.Value, variation-point={short-label=vpIN_VePMDR_e_PMM_PowerMode_Value, sw-syscond=1}
              IN_VePMTR_e_ThrmlDevEnbl_Value: accessed-variable=VePMTR_e_ThrmlDevEnbl.Value, variation-point={short-label=vpIN_VePMTR_e_ThrmlDevEnbl_Value, sw-syscond=1}
              IN_VeSSDR_b_PrepareToShtdwn_Value: accessed-variable=VeSSDR_b_PrepareToShtdwn.Value, variation-point={short-label=vpIN_VeSSDR_b_PrepareToShtdwn_Value, sw-syscond=1}
              IN_VeTAIR_I_HVAC_ECVD_CurrentAct_Value: accessed-variable=VeTAIR_I_HVAC_ECVD_CurrentAct.Value, variation-point={short-label=vpIN_VeTAIR_I_HVAC_ECVD_CurrentAct_Value, sw-syscond=1}
              IN_VeTAIR_Pct_CPV_Cmd_Value: accessed-variable=VeTAIR_Pct_CPV_Cmd.Value, variation-point={short-label=vpIN_VeTAIR_Pct_CPV_Cmd_Value, sw-syscond=1}
              IN_VeTAIR_Pct_EEXV_Cmd_Value: accessed-variable=VeTAIR_Pct_EEXV_Cmd.Value, variation-point={short-label=vpIN_VeTAIR_Pct_EEXV_Cmd_Value, sw-syscond=1}
              IN_VeTAIR_Pct_EEXV_PosAct_Value: accessed-variable=VeTAIR_Pct_EEXV_PosAct.Value, variation-point={short-label=vpIN_VeTAIR_Pct_EEXV_PosAct_Value, sw-syscond=1}
              IN_VeTAIR_Pct_EXV_Cmd_Value: accessed-variable=VeTAIR_Pct_EXV_Cmd.Value, variation-point={short-label=vpIN_VeTAIR_Pct_EXV_Cmd_Value, sw-syscond=1}
              IN_VeTAIR_Pct_EXV_PosAct_Value: accessed-variable=VeTAIR_Pct_EXV_PosAct.Value, variation-point={short-label=vpIN_VeTAIR_Pct_EXV_PosAct_Value, sw-syscond=1}
              IN_VeTAIR_Pct_FrWyVlv_PstnAct_Value: accessed-variable=VeTAIR_Pct_FrWyVlv_PstnAct.Value, variation-point={short-label=vpIN_VeTAIR_Pct_FrWyVlv_PstnAct_Value, sw-syscond=1}
              IN_VeTAIR_Pct_HTL_BypsVlv_ActlPstn_Value: accessed-variable=VeTAIR_Pct_HTL_BypsVlv_ActlPstn.Value, variation-point={short-label=vpIN_VeTAIR_Pct_HTL_BypsVlv_ActlPstn_Value, sw-syscond=1}
              IN_VeTAIR_Pct_HTL_BypsVlv_Cmd_Value: accessed-variable=VeTAIR_Pct_HTL_BypsVlv_Cmd.Value, variation-point={short-label=vpIN_VeTAIR_Pct_HTL_BypsVlv_Cmd_Value, sw-syscond=1}
              IN_VeTAIR_Pct_HT_CabVlvCmd_Value: accessed-variable=VeTAIR_Pct_HT_CabVlvCmd.Value, variation-point={short-label=vpIN_VeTAIR_Pct_HT_CabVlvCmd_Value, sw-syscond=1}
              IN_VeTAIR_Pct_LTR_BypsVlv_ActlPstn_Value: accessed-variable=VeTAIR_Pct_LTR_BypsVlv_ActlPstn.Value, variation-point={short-label=vpIN_VeTAIR_Pct_LTR_BypsVlv_ActlPstn_Value, sw-syscond=1}
              IN_VeTAIR_Pct_LTR_BypsVlv_Cmd_Value: accessed-variable=VeTAIR_Pct_LTR_BypsVlv_Cmd.Value, variation-point={short-label=vpIN_VeTAIR_Pct_LTR_BypsVlv_Cmd_Value, sw-syscond=1}
              IN_VeTAIR_Pct_OEXV_Cmd_Value: accessed-variable=VeTAIR_Pct_OEXV_Cmd.Value, variation-point={short-label=vpIN_VeTAIR_Pct_OEXV_Cmd_Value, sw-syscond=1}
              IN_VeTAIR_T_CEXV_OutTempSens_Value: accessed-variable=VeTAIR_T_CEXV_OutTempSens.Value, variation-point={short-label=vpIN_VeTAIR_T_CEXV_OutTempSens_Value, sw-syscond=1}
              IN_VeTAIR_T_EEXV_RefTemp_Value: accessed-variable=VeTAIR_T_EEXV_RefTemp.Value, variation-point={short-label=vpIN_VeTAIR_T_EEXV_RefTemp_Value, sw-syscond=1}
              IN_VeTAIR_T_EXV_RefTemp_Value: accessed-variable=VeTAIR_T_EXV_RefTemp.Value, variation-point={short-label=vpIN_VeTAIR_T_EXV_RefTemp_Value, sw-syscond=1}
              IN_VeTAIR_T_FtEvapTmp_Value: accessed-variable=VeTAIR_T_FtEvapTmp.Value, variation-point={short-label=vpIN_VeTAIR_T_FtEvapTmp_Value, sw-syscond=1}
              IN_VeTAIR_T_FtEvapTmp_Tgt_Value: accessed-variable=VeTAIR_T_FtEvapTmp_Tgt.Value, variation-point={short-label=vpIN_VeTAIR_T_FtEvapTmp_Tgt_Value, sw-syscond=1}
              IN_VeTAIR_T_HtrCoreTmp_Tgt_Value: accessed-variable=VeTAIR_T_HtrCoreTmp_Tgt.Value, variation-point={short-label=vpIN_VeTAIR_T_HtrCoreTmp_Tgt_Value, sw-syscond=1}
              IN_VeTAIR_T_OEXV_InTempSens_Value: accessed-variable=VeTAIR_T_OEXV_InTempSens.Value, variation-point={short-label=vpIN_VeTAIR_T_OEXV_InTempSens_Value, sw-syscond=1}
              IN_VeTAIR_T_OEXV_OutTempSens_Value: accessed-variable=VeTAIR_T_OEXV_OutTempSens.Value, variation-point={short-label=vpIN_VeTAIR_T_OEXV_OutTempSens_Value, sw-syscond=1}
              IN_VeTAIR_U_HT_CabVlvSts_Value: accessed-variable=VeTAIR_U_HT_CabVlvSts.Value, variation-point={short-label=vpIN_VeTAIR_U_HT_CabVlvSts_Value, sw-syscond=1}
              IN_VeTAIR_b_Chlr_SO_VlvCmd_Value: accessed-variable=VeTAIR_b_Chlr_SO_VlvCmd.Value, variation-point={short-label=vpIN_VeTAIR_b_Chlr_SO_VlvCmd_Value, sw-syscond=1}
              IN_VeTAIR_b_DVC_EEXV_Calibration_Start_Value: accessed-variable=VeTAIR_b_DVC_EEXV_Calibration_Start.Value, variation-point={short-label=vpIN_VeTAIR_b_DVC_EEXV_Calibration_Start_Value, sw-syscond=1}
              IN_VeTAIR_b_DVC_EXV_Calibration_Start_Value: accessed-variable=VeTAIR_b_DVC_EXV_Calibration_Start.Value, variation-point={short-label=vpIN_VeTAIR_b_DVC_EXV_Calibration_Start_Value, sw-syscond=1}
              IN_VeTAIR_b_DVC_OEXV_Calibration_Start_Value: accessed-variable=VeTAIR_b_DVC_OEXV_Calibration_Start.Value, variation-point={short-label=vpIN_VeTAIR_b_DVC_OEXV_Calibration_Start_Value, sw-syscond=1}
              IN_VeTAIR_b_EXV_PosAct_FA_Value: accessed-variable=VeTAIR_b_EXV_PosAct_FA.Value, variation-point={short-label=vpIN_VeTAIR_b_EXV_PosAct_FA_Value, sw-syscond=1}
              IN_VeTAIR_b_EXV_RefPress_FA_Value: accessed-variable=VeTAIR_b_EXV_RefPress_FA.Value, variation-point={short-label=vpIN_VeTAIR_b_EXV_RefPress_FA_Value, sw-syscond=1}
              IN_VeTAIR_b_EXV_RefTemp_FA_Value: accessed-variable=VeTAIR_b_EXV_RefTemp_FA.Value, variation-point={short-label=vpIN_VeTAIR_b_EXV_RefTemp_FA_Value, sw-syscond=1}
              IN_VeTAIR_b_EXV_RspErr_Value: accessed-variable=VeTAIR_b_EXV_RspErr.Value, variation-point={short-label=vpIN_VeTAIR_b_EXV_RspErr_Value, sw-syscond=1}
              IN_VeTAIR_b_FrWyVlv_PstnAct_FA_Value: accessed-variable=VeTAIR_b_FrWyVlv_PstnAct_FA.Value, variation-point={short-label=vpIN_VeTAIR_b_FrWyVlv_PstnAct_FA_Value, sw-syscond=1}
              IN_VeTAIR_b_FtEvapTmp_FA_Value: accessed-variable=VeTAIR_b_FtEvapTmp_FA.Value, variation-point={short-label=vpIN_VeTAIR_b_FtEvapTmp_FA_Value, sw-syscond=1}
              IN_VeTAIR_b_FtEvapTmp_TgtFA_Value: accessed-variable=VeTAIR_b_FtEvapTmp_TgtFA.Value, variation-point={short-label=vpIN_VeTAIR_b_FtEvapTmp_TgtFA_Value, sw-syscond=1}
              IN_VeTAIR_b_Ft_SO_VlvCmd_Value: accessed-variable=VeTAIR_b_Ft_SO_VlvCmd.Value, variation-point={short-label=vpIN_VeTAIR_b_Ft_SO_VlvCmd_Value, sw-syscond=1}
              IN_VeTAIR_b_HTL_BypsVlv_ActlPstn_FA_Value: accessed-variable=VeTAIR_b_HTL_BypsVlv_ActlPstn_FA.Value, variation-point={short-label=vpIN_VeTAIR_b_HTL_BypsVlv_ActlPstn_FA_Value, sw-syscond=1}
              IN_VeTAIR_b_HT_Shtoff_VlvCmd_Value: accessed-variable=VeTAIR_b_HT_Shtoff_VlvCmd.Value, variation-point={short-label=vpIN_VeTAIR_b_HT_Shtoff_VlvCmd_Value, sw-syscond=1}
              IN_VeTAIR_b_LTR_BypsVlv_ActlPstn_FA_Value: accessed-variable=VeTAIR_b_LTR_BypsVlv_ActlPstn_FA.Value, variation-point={short-label=vpIN_VeTAIR_b_LTR_BypsVlv_ActlPstn_FA_Value, sw-syscond=1}
              IN_VeTAIR_b_LT_Shtoff_VlvCmd_Value: accessed-variable=VeTAIR_b_LT_Shtoff_VlvCmd.Value, variation-point={short-label=vpIN_VeTAIR_b_LT_Shtoff_VlvCmd_Value, sw-syscond=1}
              IN_VeTAIR_e_CPV_IO_Cnt_Value: accessed-variable=VeTAIR_e_CPV_IO_Cnt.Value, variation-point={short-label=vpIN_VeTAIR_e_CPV_IO_Cnt_Value, sw-syscond=1}
              IN_VeTAIR_e_Chlr_SO_VlvCmd_IO_Cnt_Value: accessed-variable=VeTAIR_e_Chlr_SO_VlvCmd_IO_Cnt.Value, variation-point={short-label=vpIN_VeTAIR_e_Chlr_SO_VlvCmd_IO_Cnt_Value, sw-syscond=1}
              IN_VeTAIR_e_DVC_HTCV_CalibStrt_Value: accessed-variable=VeTAIR_e_DVC_HTCV_CalibStrt.Value, variation-point={short-label=vpIN_VeTAIR_e_DVC_HTCV_CalibStrt_Value, sw-syscond=1}
              IN_VeTAIR_e_EEXV_CalStat_Value: accessed-variable=VeTAIR_e_EEXV_CalStat.Value, variation-point={short-label=vpIN_VeTAIR_e_EEXV_CalStat_Value, sw-syscond=1}
              IN_VeTAIR_e_EEXV_IO_CntrlSt_Value: accessed-variable=VeTAIR_e_EEXV_IO_CntrlSt.Value, variation-point={short-label=vpIN_VeTAIR_e_EEXV_IO_CntrlSt_Value, sw-syscond=1}
              IN_VeTAIR_e_EEXV_Sts_Value: accessed-variable=VeTAIR_e_EEXV_Sts.Value, variation-point={short-label=vpIN_VeTAIR_e_EEXV_Sts_Value, sw-syscond=1}
              IN_VeTAIR_e_EXV_CalStat_Value: accessed-variable=VeTAIR_e_EXV_CalStat.Value, variation-point={short-label=vpIN_VeTAIR_e_EXV_CalStat_Value, sw-syscond=1}
              IN_VeTAIR_e_EXV_Err_Value: accessed-variable=VeTAIR_e_EXV_Err.Value, variation-point={short-label=vpIN_VeTAIR_e_EXV_Err_Value, sw-syscond=1}
              IN_VeTAIR_e_EXV_IO_CntrlSt_Value: accessed-variable=VeTAIR_e_EXV_IO_CntrlSt.Value, variation-point={short-label=vpIN_VeTAIR_e_EXV_IO_CntrlSt_Value, sw-syscond=1}
              IN_VeTAIR_e_EXV_Sts_Value: accessed-variable=VeTAIR_e_EXV_Sts.Value, variation-point={short-label=vpIN_VeTAIR_e_EXV_Sts_Value, sw-syscond=1}
              IN_VeTAIR_e_FrWyVlv_CalSts_Value: accessed-variable=VeTAIR_e_FrWyVlv_CalSts.Value, variation-point={short-label=vpIN_VeTAIR_e_FrWyVlv_CalSts_Value, sw-syscond=1}
              IN_VeTAIR_e_FrWyVlv_ErrSts_Value: accessed-variable=VeTAIR_e_FrWyVlv_ErrSts.Value, variation-point={short-label=vpIN_VeTAIR_e_FrWyVlv_ErrSts_Value, sw-syscond=1}
              IN_VeTAIR_e_Ft_SO_VlvCmd_IO_Cnt_Value: accessed-variable=VeTAIR_e_Ft_SO_VlvCmd_IO_Cnt.Value, variation-point={short-label=vpIN_VeTAIR_e_Ft_SO_VlvCmd_IO_Cnt_Value, sw-syscond=1}
              IN_VeTAIR_e_HTL_BypsVlv_CalSts_Value: accessed-variable=VeTAIR_e_HTL_BypsVlv_CalSts.Value, variation-point={short-label=vpIN_VeTAIR_e_HTL_BypsVlv_CalSts_Value, sw-syscond=1}
              IN_VeTAIR_e_HTL_BypsVlv_ErrSts_Value: accessed-variable=VeTAIR_e_HTL_BypsVlv_ErrSts.Value, variation-point={short-label=vpIN_VeTAIR_e_HTL_BypsVlv_ErrSts_Value, sw-syscond=1}
              IN_VeTAIR_e_HTL_BypsVlv_IO_CntrlSt_Value: accessed-variable=VeTAIR_e_HTL_BypsVlv_IO_CntrlSt.Value, variation-point={short-label=vpIN_VeTAIR_e_HTL_BypsVlv_IO_CntrlSt_Value, sw-syscond=1}
              IN_VeTAIR_e_HT_CabVlvCmd_IO_Cnt_Value: accessed-variable=VeTAIR_e_HT_CabVlvCmd_IO_Cnt.Value, variation-point={short-label=vpIN_VeTAIR_e_HT_CabVlvCmd_IO_Cnt_Value, sw-syscond=1}
              IN_VeTAIR_e_HT_Shtoff_VlvCmd_IO_CntrlSt_Value: accessed-variable=VeTAIR_e_HT_Shtoff_VlvCmd_IO_CntrlSt.Value, variation-point={short-label=vpIN_VeTAIR_e_HT_Shtoff_VlvCmd_IO_CntrlSt_Value, sw-syscond=1}
              IN_VeTAIR_e_LTR_BypsVlv_CalSts_Value: accessed-variable=VeTAIR_e_LTR_BypsVlv_CalSts.Value, variation-point={short-label=vpIN_VeTAIR_e_LTR_BypsVlv_CalSts_Value, sw-syscond=1}
              IN_VeTAIR_e_LTR_BypsVlv_ErrSts_Value: accessed-variable=VeTAIR_e_LTR_BypsVlv_ErrSts.Value, variation-point={short-label=vpIN_VeTAIR_e_LTR_BypsVlv_ErrSts_Value, sw-syscond=1}
              IN_VeTAIR_e_LTR_BypsVlv_IO_CntrlSt_Value: accessed-variable=VeTAIR_e_LTR_BypsVlv_IO_CntrlSt.Value, variation-point={short-label=vpIN_VeTAIR_e_LTR_BypsVlv_IO_CntrlSt_Value, sw-syscond=1}
              IN_VeTAIR_e_LT_Shtoff_VlvCmd_IO_CntrlSt_Value: accessed-variable=VeTAIR_e_LT_Shtoff_VlvCmd_IO_CntrlSt.Value, variation-point={short-label=vpIN_VeTAIR_e_LT_Shtoff_VlvCmd_IO_CntrlSt_Value, sw-syscond=1}
              IN_VeTAIR_e_OEXV_CalStat_Value: accessed-variable=VeTAIR_e_OEXV_CalStat.Value, variation-point={short-label=vpIN_VeTAIR_e_OEXV_CalStat_Value, sw-syscond=1}
              IN_VeTAIR_e_OEXV_IO_CntrlSt_Value: accessed-variable=VeTAIR_e_OEXV_IO_CntrlSt.Value, variation-point={short-label=vpIN_VeTAIR_e_OEXV_IO_CntrlSt_Value, sw-syscond=1}
              IN_VeTAIR_e_OEXV_Sts_Value: accessed-variable=VeTAIR_e_OEXV_Sts.Value, variation-point={short-label=vpIN_VeTAIR_e_OEXV_Sts_Value, sw-syscond=1}
              IN_VeTAIR_n_CompSpdFdb_Value: accessed-variable=VeTAIR_n_CompSpdFdb.Value, variation-point={short-label=vpIN_VeTAIR_n_CompSpdFdb_Value, sw-syscond=1}
              IN_VeTAIR_p_CEXV_OutPressSens_Value: accessed-variable=VeTAIR_p_CEXV_OutPressSens.Value, variation-point={short-label=vpIN_VeTAIR_p_CEXV_OutPressSens_Value, sw-syscond=1}
              IN_VeTAIR_p_EEXV_RefPress_Value: accessed-variable=VeTAIR_p_EEXV_RefPress.Value, variation-point={short-label=vpIN_VeTAIR_p_EEXV_RefPress_Value, sw-syscond=1}
              IN_VeTAIR_p_EXV_RefPress_Value: accessed-variable=VeTAIR_p_EXV_RefPress.Value, variation-point={short-label=vpIN_VeTAIR_p_EXV_RefPress_Value, sw-syscond=1}
              IN_VeTAIR_p_HghRfrgtPres_Value: accessed-variable=VeTAIR_p_HghRfrgtPres.Value, variation-point={short-label=vpIN_VeTAIR_p_HghRfrgtPres_Value, sw-syscond=1}
              IN_VeTAIR_p_OEXV_OutPressSens_Value: accessed-variable=VeTAIR_p_OEXV_OutPressSens.Value, variation-point={short-label=vpIN_VeTAIR_p_OEXV_OutPressSens_Value, sw-syscond=1}
              IN_VeTHMR_Pct_ClntProp3WyVlv_Cmd_Value: accessed-variable=VeTHMR_Pct_ClntProp3WyVlv_Cmd.Value, variation-point={short-label=vpIN_VeTHMR_Pct_ClntProp3WyVlv_Cmd_Value, sw-syscond=1}
              IN_VeTHMR_Pct_HTL_BypsVlv_Cmd_Value: accessed-variable=VeTHMR_Pct_HTL_BypsVlv_Cmd.Value, variation-point={short-label=vpIN_VeTHMR_Pct_HTL_BypsVlv_Cmd_Value, sw-syscond=1}
              IN_VeTHMR_Pct_LINPrpVlv_Cmd_Value: accessed-variable=VeTHMR_Pct_LINPrpVlv_Cmd.Value, variation-point={short-label=vpIN_VeTHMR_Pct_LINPrpVlv_Cmd_Value, sw-syscond=1}
              IN_VeTHMR_Pct_LTL_Vlv_Cmd_Value: accessed-variable=VeTHMR_Pct_LTL_Vlv_Cmd.Value, variation-point={short-label=vpIN_VeTHMR_Pct_LTL_Vlv_Cmd_Value, sw-syscond=1}
              IN_VeTHMR_b_DeiceActv_Value: accessed-variable=VeTHMR_b_DeiceActv.Value, variation-point={short-label=vpIN_VeTHMR_b_DeiceActv_Value, sw-syscond=1}
              IN_VeTHMR_b_HTCV_LearnEnb_Value: accessed-variable=VeTHMR_b_HTCV_LearnEnb.Value, variation-point={short-label=vpIN_VeTHMR_b_HTCV_LearnEnb_Value, sw-syscond=1}
              IN_VeTHMR_b_LINPrpVlv_SvReq_Value: accessed-variable=VeTHMR_b_LINPrpVlv_SvReq.Value, variation-point={short-label=vpIN_VeTHMR_b_LINPrpVlv_SvReq_Value, sw-syscond=1}
              IN_VeTHMR_e_BatThrmlSt_Value: accessed-variable=VeTHMR_e_BatThrmlSt.Value, variation-point={short-label=vpIN_VeTHMR_e_BatThrmlSt_Value, sw-syscond=1}
              IN_VeTHMR_e_CabCoolThermalState_Value: accessed-variable=VeTHMR_e_CabCoolThermalState.Value, variation-point={short-label=vpIN_VeTHMR_e_CabCoolThermalState_Value, sw-syscond=1}
              IN_VeTHMR_e_CabHeatThermalMode_Value: accessed-variable=VeTHMR_e_CabHeatThermalMode.Value, variation-point={short-label=vpIN_VeTHMR_e_CabHeatThermalMode_Value, sw-syscond=1}
              IN_VeTHMR_e_CabThermalMode_Value: accessed-variable=VeTHMR_e_CabThermalMode.Value, variation-point={short-label=vpIN_VeTHMR_e_CabThermalMode_Value, sw-syscond=1}
              IN_VeTHMR_e_ClntNProp3WyVlv_State_Value: accessed-variable=VeTHMR_e_ClntNProp3WyVlv_State.Value, variation-point={short-label=vpIN_VeTHMR_e_ClntNProp3WyVlv_State_Value, sw-syscond=1}
              IN_VeTHMR_e_ClntProp3WyVlv_State_Value: accessed-variable=VeTHMR_e_ClntProp3WyVlv_State.Value, variation-point={short-label=vpIN_VeTHMR_e_ClntProp3WyVlv_State_Value, sw-syscond=1}
              IN_VeTHMR_e_EngOrBattPwrDschg_State_Value: accessed-variable=VeTHMR_e_EngOrBattPwrDschg_State.Value, variation-point={short-label=vpIN_VeTHMR_e_EngOrBattPwrDschg_State_Value, sw-syscond=1}
              IN_VeTHMR_e_LTCLThrmlMode_Value: accessed-variable=VeTHMR_e_LTCLThrmlMode.Value, variation-point={short-label=vpIN_VeTHMR_e_LTCLThrmlMode_Value, sw-syscond=1}
              IN_VeTHMR_e_RefShtoffVlv_State_Value: accessed-variable=VeTHMR_e_RefShtoffVlv_State.Value, variation-point={short-label=vpIN_VeTHMR_e_RefShtoffVlv_State_Value, sw-syscond=1}
              IN_VeTRIR_T_HtrCorClnt_TmpIn_Value: accessed-variable=VeTRIR_T_HtrCorClnt_TmpIn.Value, variation-point={short-label=vpIN_VeTRIR_T_HtrCorClnt_TmpIn_Value, sw-syscond=1}
              IN_VeTRIR_b_HtrCorClnt_TmpIn_FA_Value: accessed-variable=VeTRIR_b_HtrCorClnt_TmpIn_FA.Value, variation-point={short-label=vpIN_VeTRIR_b_HtrCorClnt_TmpIn_FA_Value, sw-syscond=1}
              IN_VeVLDR_b_EXV_PressElctrFlt_FltDtct_Value: accessed-variable=VeVLDR_b_EXV_PressElctrFlt_FltDtct.Value, variation-point={short-label=vpIN_VeVLDR_b_EXV_PressElctrFlt_FltDtct_Value, sw-syscond=1}
              IN_VeVLDR_b_EXV_PressSens_FltDtct_Value: accessed-variable=VeVLDR_b_EXV_PressSens_FltDtct.Value, variation-point={short-label=vpIN_VeVLDR_b_EXV_PressSens_FltDtct_Value, sw-syscond=1}
              IN_VeVLDR_b_EXV_PressShrtHigh_Value: accessed-variable=VeVLDR_b_EXV_PressShrtHigh.Value, variation-point={short-label=vpIN_VeVLDR_b_EXV_PressShrtHigh_Value, sw-syscond=1}
              IN_VeVLDR_b_EXV_TempElctrFlt_FltDtct_Value: accessed-variable=VeVLDR_b_EXV_TempElctrFlt_FltDtct.Value, variation-point={short-label=vpIN_VeVLDR_b_EXV_TempElctrFlt_FltDtct_Value, sw-syscond=1}
              IN_VeVLDR_b_EXV_TempSens_FltDtct_Value: accessed-variable=VeVLDR_b_EXV_TempSens_FltDtct.Value, variation-point={short-label=vpIN_VeVLDR_b_EXV_TempSens_FltDtct_Value, sw-syscond=1}
              IN_VeVLDR_b_HCTV_Leak_FltDtct_Value: accessed-variable=VeVLDR_b_HCTV_Leak_FltDtct.Value, variation-point={short-label=vpIN_VeVLDR_b_HCTV_Leak_FltDtct_Value, sw-syscond=1}
              IN_VeVLDR_b_HTCV_Stck_FltDtct_Value: accessed-variable=VeVLDR_b_HTCV_Stck_FltDtct.Value, variation-point={short-label=vpIN_VeVLDR_b_HTCV_Stck_FltDtct_Value, sw-syscond=1}
              IN_VeVLDR_b_HTSoV_StkCls_FltDtct_Value: accessed-variable=VeVLDR_b_HTSoV_StkCls_FltDtct.Value, variation-point={short-label=vpIN_VeVLDR_b_HTSoV_StkCls_FltDtct_Value, sw-syscond=1}
              IN_VeVLDR_b_HTSoV_StkCls_XYEnbl_Value: accessed-variable=VeVLDR_b_HTSoV_StkCls_XYEnbl.Value, variation-point={short-label=vpIN_VeVLDR_b_HTSoV_StkCls_XYEnbl_Value, sw-syscond=1}
              IN_VeVLDR_b_HTSoV_StkOpn_FltDtct_Value: accessed-variable=VeVLDR_b_HTSoV_StkOpn_FltDtct.Value, variation-point={short-label=vpIN_VeVLDR_b_HTSoV_StkOpn_FltDtct_Value, sw-syscond=1}
              IN_VeVLDR_b_HTSoV_StkOpn_XYEnbl_Value: accessed-variable=VeVLDR_b_HTSoV_StkOpn_XYEnbl.Value, variation-point={short-label=vpIN_VeVLDR_b_HTSoV_StkOpn_XYEnbl_Value, sw-syscond=1}
          data-send-points:
            49 x access:
              OUT_VeRCVR_b_FtRfgtShtoff_VlvCmd_Value: accessed-variable=VeRCVR_b_FtRfgtShtoff_VlvCmd.Value
              OUT_VeRCVR_b_FtRfgtShtoff_VlvSts_Value: accessed-variable=VeRCVR_b_FtRfgtShtoff_VlvSts.Value
              OUT_VeRCVR_b_HT_CabVlvRely_Sts_Value: accessed-variable=VeRCVR_b_HT_CabVlvRely_Sts.Value
              OUT_VeRCVR_b_HTCV_Learning_Req_Value: accessed-variable=VeRCVR_b_HTCV_Learning_Req.Value
              OUT_VeRCVR_Pct_FrWyVlv_PstnCmnd_Value: accessed-variable=VeRCVR_Pct_FrWyVlv_PstnCmnd.Value
              OUT_VeRCVR_e_FrWyVlv_CalCmnd_Value: accessed-variable=VeRCVR_e_FrWyVlv_CalCmnd.Value
              OUT_VeRCVR_b_FrWyVlv_PstnSv_Value: accessed-variable=VeRCVR_b_FrWyVlv_PstnSv.Value
              OUT_VeRCVR_e_CPV_RtnSts_Value: accessed-variable=VeRCVR_e_CPV_RtnSts.Value
              OUT_VeRCVR_Pct_EXV_PosRq_Value: accessed-variable=VeRCVR_Pct_EXV_PosRq.Value
              OUT_VeRCVR_e_EXV_CalCmd_Value: accessed-variable=VeRCVR_e_EXV_CalCmd.Value
              OUT_VeRCVR_b_AC_ShtdwnRqst_Value: accessed-variable=VeRCVR_b_AC_ShtdwnRqst.Value
              OUT_VeRCVR_b_Chlr_OpenCompTransition_Value: accessed-variable=VeRCVR_b_Chlr_OpenCompTransition.Value
              OUT_VeRCVR_b_RSVCompTransition_Value: accessed-variable=VeRCVR_b_RSVCompTransition.Value
              OUT_VeRCVR_Pct_LTR_Vlv_PstnCmnd_Value: accessed-variable=VeRCVR_Pct_LTR_Vlv_PstnCmnd.Value
              OUT_VeRCVR_e_LTR_Vlv_CalCmnd_Value: accessed-variable=VeRCVR_e_LTR_Vlv_CalCmnd.Value
              OUT_VeRCVR_b_LTR_Vlv_PstnSv_Value: accessed-variable=VeRCVR_b_LTR_Vlv_PstnSv.Value
              OUT_VeRCVR_Pct_HTL_Vlv_PstnCmnd_Value: accessed-variable=VeRCVR_Pct_HTL_Vlv_PstnCmnd.Value
              OUT_VeRCVR_e_HTL_Vlv_CalCmnd_Value: accessed-variable=VeRCVR_e_HTL_Vlv_CalCmnd.Value
              OUT_VeRCVR_b_HTL_Vlv_PstnSv_Value: accessed-variable=VeRCVR_b_HTL_Vlv_PstnSv.Value
              OUT_VeRCVR_e_EXV_RtnSts_Value: accessed-variable=VeRCVR_e_EXV_RtnSts.Value
              OUT_VeRCVR_e_CPV_Valve_Stuck_State_Value: accessed-variable=VeRCVR_e_CPV_Valve_Stuck_State.Value
              OUT_VeRCVR_e_LTR_Valve_Stuck_State_Value: accessed-variable=VeRCVR_e_LTR_Valve_Stuck_State.Value
              OUT_VeRCVR_e_HTL_Valve_Stuck_State_Value: accessed-variable=VeRCVR_e_HTL_Valve_Stuck_State.Value
              OUT_VeRCVR_b_ChlrRfgtShtoff_VlvCmd_Value: accessed-variable=VeRCVR_b_ChlrRfgtShtoff_VlvCmd.Value
              OUT_VeRCVR_b_EXV_PresSensrRA_Value: accessed-variable=VeRCVR_b_EXV_PresSensrRA.Value
              OUT_VeRCVR_b_RdyToShtDwn_Value: accessed-variable=VeRCVR_b_RdyToShtDwn.Value
              OUT_VeRCVR_e_EEXV_CalRq_Value: accessed-variable=VeRCVR_e_EEXV_CalRq.Value
              OUT_VeRCVR_Pct_EEXV_Cmd_Value: accessed-variable=VeRCVR_Pct_EEXV_Cmd.Value
              OUT_VeRCVR_e_OEXV_CalRq_Value: accessed-variable=VeRCVR_e_OEXV_CalRq.Value
              OUT_VeRCVR_Pct_OEXV_Cmd_Value: accessed-variable=VeRCVR_Pct_OEXV_Cmd.Value
              OUT_VeRCVR_p_eACSuctionPressure_Value: accessed-variable=VeRCVR_p_eACSuctionPressure.Value
              OUT_VeRCVR_Pct_HTR_Vlv_PstnCmnd_Value: accessed-variable=VeRCVR_Pct_HTR_Vlv_PstnCmnd.Value
              OUT_VeRCVR_e_HTR_Vlv_CalCmnd_Value: accessed-variable=VeRCVR_e_HTR_Vlv_CalCmnd.Value
              OUT_VeRCVR_e_HTRBV_Block_Det_Enbl_Value: accessed-variable=VeRCVR_e_HTRBV_Block_Det_Enbl.Value
              OUT_VeRCVR_b_ChlrRfrgtShtoff_VlvSts_Value: accessed-variable=VeRCVR_b_ChlrRfrgtShtoff_VlvSts.Value
              OUT_VeRCVR_b_HT_Shtoff_VlvCmd_Value: accessed-variable=VeRCVR_b_HT_Shtoff_VlvCmd.Value
              OUT_VeRCVR_b_HT_Shtoff_VlvSts_Value: accessed-variable=VeRCVR_b_HT_Shtoff_VlvSts.Value
              OUT_VeRCVR_e_HT_Shtoff_VlvSts_Value: accessed-variable=VeRCVR_e_HT_Shtoff_VlvSts.Value
              OUT_VeRCVR_Pct_HT_CabVlvCmd_Value: accessed-variable=VeRCVR_Pct_HT_CabVlvCmd.Value
              OUT_VeRCVR_Pct_HT_CabVlvSts_Value: accessed-variable=VeRCVR_Pct_HT_CabVlvSts.Value
              OUT_VeRCVR_e_EEXV_RtnSts_Value: accessed-variable=VeRCVR_e_EEXV_RtnSts.Value
              OUT_VeRCVR_e_OEXV_RtnSts_Value: accessed-variable=VeRCVR_e_OEXV_RtnSts.Value
              OUT_VeRCVR_e_LTR_RtnSts_Value: accessed-variable=VeRCVR_e_LTR_RtnSts.Value
              OUT_VeRCVR_e_HTL_RtnSts_Value: accessed-variable=VeRCVR_e_HTL_RtnSts.Value
              OUT_VeRCVR_Pct_HtrCoreBypVlv_PstnCmnd_Value: accessed-variable=VeRCVR_Pct_HtrCoreBypVlv_PstnCmnd.Value
              OUT_VeRCVR_e_HtrCoreBypVlv_CalCmnd_Value: accessed-variable=VeRCVR_e_HtrCoreBypVlv_CalCmnd.Value
              OUT_VeRCVR_b_HtrCoreBypVlv_PstnSv_Value: accessed-variable=VeRCVR_b_HtrCoreBypVlv_PstnSv.Value
              OUT_VeRCVR_e_HtrCoreBypVlv_Stuck_State_Value: accessed-variable=VeRCVR_e_HtrCoreBypVlv_Stuck_State.Value
              OUT_VeRCVR_Pct_CAC_BypVlv_PstnCmd_Value: accessed-variable=VeRCVR_Pct_CAC_BypVlv_PstnCmd.Value
        RCVR_PwrOff
          data-send-points:
            11 x access:
              OUT_EeRCVR_U_HT_CabVlvSts_Min_EeRCVR_U_HT_CabVlvSts_Min: accessed-variable=EeRCVR_U_HT_CabVlvSts_Min.EeRCVR_U_HT_CabVlvSts_Min
              OUT_NeRCVR_Cnt_HTL_CntrlrShtDwn_Cycles_NeRCVR_Cnt_HTL_CntrlrShtDwn_Cycles: accessed-variable=NeRCVR_Cnt_HTL_CntrlrShtDwn_Cycles.NeRCVR_Cnt_HTL_CntrlrShtDwn_Cycles
              OUT_EeRCVR_Cnt_OEXV_CyclesSncCal_EeRCVR_Cnt_OEXV_CyclesSncCal: accessed-variable=EeRCVR_Cnt_OEXV_CyclesSncCal.EeRCVR_Cnt_OEXV_CyclesSncCal
              OUT_EeRCVR_U_HT_CabVlvSts_Max_EeRCVR_U_HT_CabVlvSts_Max: accessed-variable=EeRCVR_U_HT_CabVlvSts_Max.EeRCVR_U_HT_CabVlvSts_Max
              OUT_EeRCVR_Cnt_EEXV_CyclesSncCal_EeRCVR_Cnt_EEXV_CyclesSncCal: accessed-variable=EeRCVR_Cnt_EEXV_CyclesSncCal.EeRCVR_Cnt_EEXV_CyclesSncCal
              OUT_EeRCVR_Cnt_HTCV_Endstophits_EeRCVR_Cnt_HTCV_Endstophits: accessed-variable=EeRCVR_Cnt_HTCV_Endstophits.EeRCVR_Cnt_HTCV_Endstophits
              OUT_EeRCVR_e_HTCV_Calibration_Sts_EeRCVR_e_HTCV_Calibration_Sts: accessed-variable=EeRCVR_e_HTCV_Calibration_Sts.EeRCVR_e_HTCV_Calibration_Sts
              OUT_NeRCVR_Cnt_CPV_CntrlrShtDwn_Cycles_NeRCVR_Cnt_CPV_CntrlrShtDwn_Cycles: accessed-variable=NeRCVR_Cnt_CPV_CntrlrShtDwn_Cycles.NeRCVR_Cnt_CPV_CntrlrShtDwn_Cycles
              OUT_EeRCVR_Cnt_EXV_CyclesSncCal_EeRCVR_Cnt_EXV_CyclesSncCal: accessed-variable=EeRCVR_Cnt_EXV_CyclesSncCal.EeRCVR_Cnt_EXV_CyclesSncCal
              OUT_NeRCVR_Cnt_LTR_CntrlrShtDwn_Cycles_NeRCVR_Cnt_LTR_CntrlrShtDwn_Cycles: accessed-variable=NeRCVR_Cnt_LTR_CntrlrShtDwn_Cycles.NeRCVR_Cnt_LTR_CntrlrShtDwn_Cycles
              OUT_NeRCVR_Cnt_HtrCore_CntrlrShtDwn_Cycles_NeRCVR_Cnt_HtrCore_CntrlrShtDwn_Cycles: accessed-variable=NeRCVR_Cnt_HtrCore_CntrlrShtDwn_Cycles.NeRCVR_Cnt_HtrCore_CntrlrShtDwn_Cycles
        Routine_RC1309_CPV_ClbrtnRtn
          data-receive-point-by-arguments:
            access IN_VeDCAB_e_Routine_RC1309_CPV_ClbrtnRtn_Op_Value: accessed-variable=VeDCAB_e_Routine_RC1309_CPV_ClbrtnRtn_Op.Value
        Routine_RC130E_LTR_ClbrtnRtn
          data-receive-point-by-arguments:
            access IN_VeDCAB_e_Routine_RC130E_LTR_ClbrtnRtn_Op_Value: accessed-variable=VeDCAB_e_Routine_RC130E_LTR_ClbrtnRtn_Op.Value
        Routine_RC130F_HTL_ClbrtnRtn
          data-receive-point-by-arguments:
            access IN_VeDCAB_e_Routine_RC130F_HTL_ClbrtnRtn_Op_Value: accessed-variable=VeDCAB_e_Routine_RC130F_HTL_ClbrtnRtn_Op.Value
      5 x variation point proxy, all with category=CONDITION:
        Variant_RCVR_FUNC_1: condition-access=0
        Variant_RCVR_FUNC_2: condition-access=1
        Variant_RCVR_FUNC_{3..5}: condition-access=0
